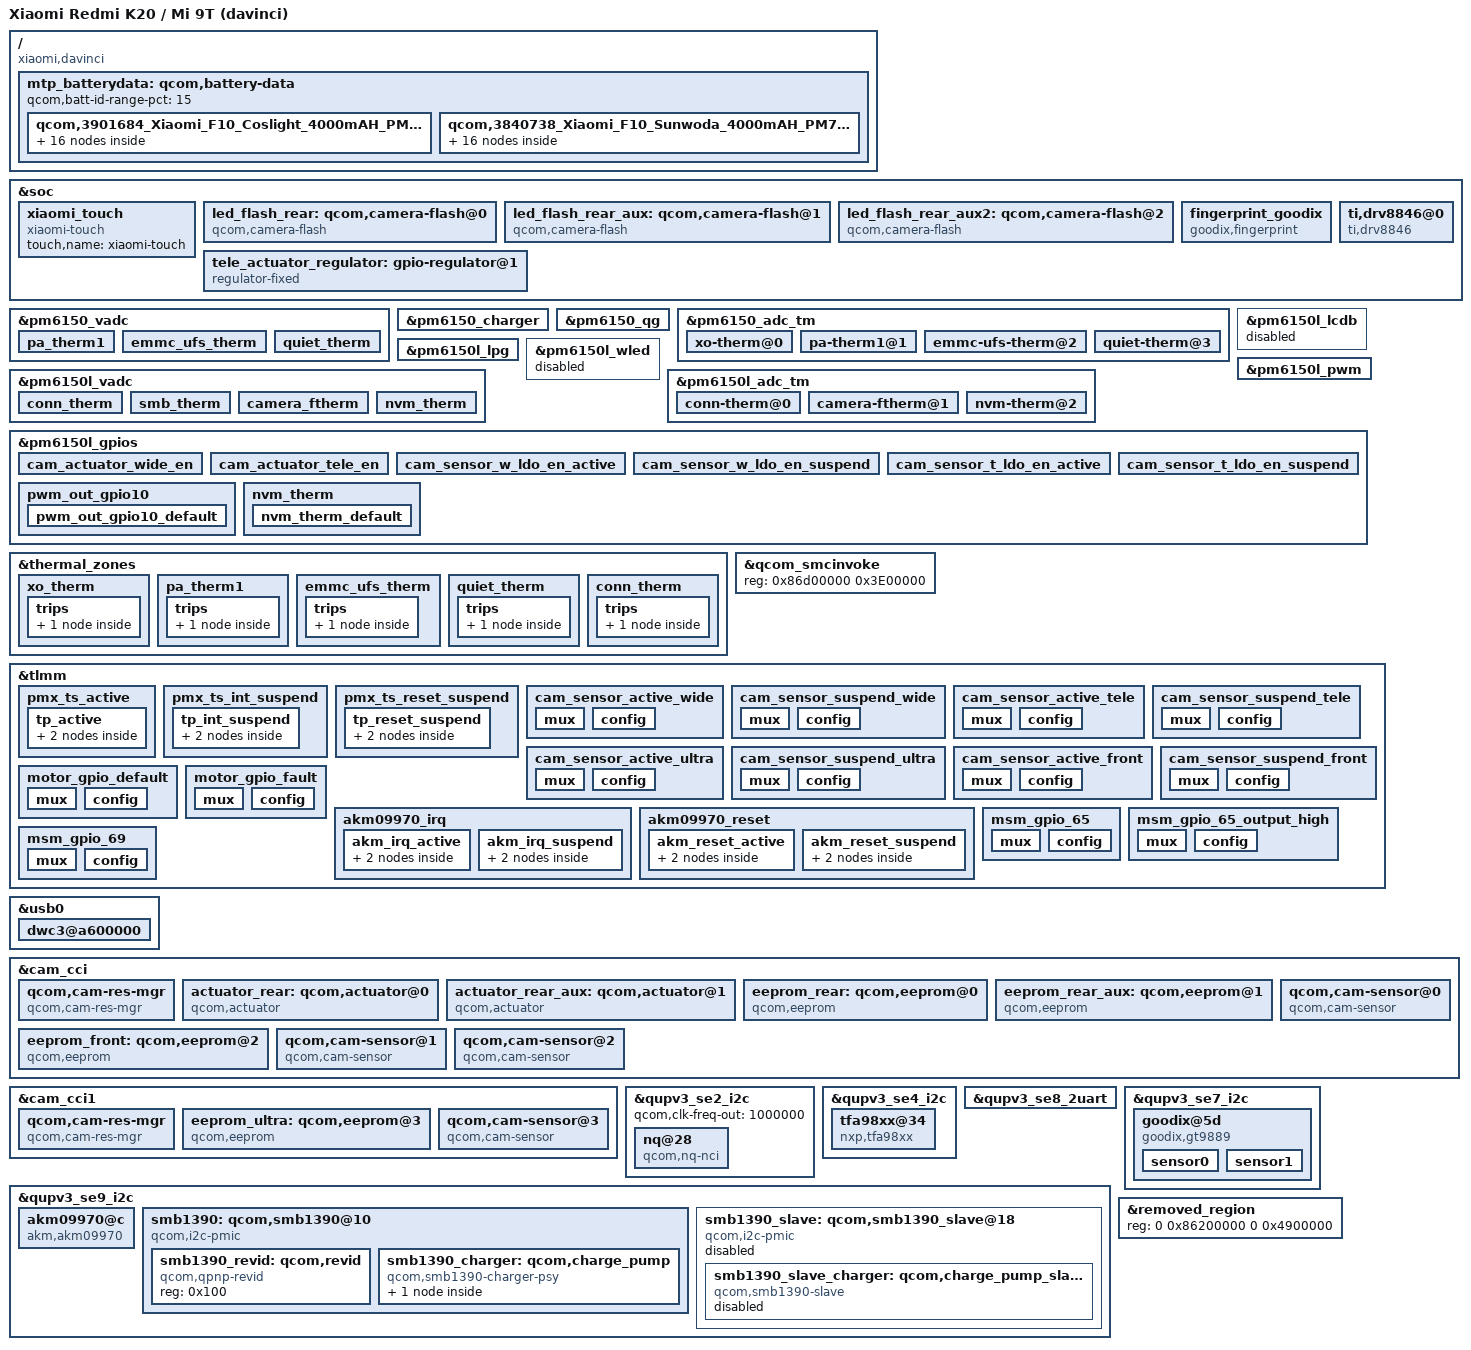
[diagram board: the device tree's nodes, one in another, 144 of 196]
/dts-v1/;

/* Generated by dtsplit.py (tools-sdmmagpie) from the 4.14 davinci files and the 6.1 violet DT. */

#include "xiaomi-sdmmagpie-common.dtsi"
#define wide_actuator_regulator tele_actuator_regulator

/ {
	/* MERGE model: 4.14 target has "DAVINCI" */
	/* MERGE compatible: 4.14 target has "qcom,sdmmagpie-qrd", "qcom,sdmmagpie", "qcom,qrd" */
	model = "Xiaomi Redmi K20 / Mi 9T (davinci)";
	compatible = "xiaomi,davinci", "qcom,sdmmagpie";
	qcom,board-id = <39 0>;

	/* davinci battery profiles (4.14 davinci-sdmmagpie.dtsi) */
	mtp_batterydata: qcom,battery-data {
		qcom,batt-id-range-pct = <15>;

		qcom,3901684_Xiaomi_F10_Coslight_4000mAH_PM7150 {
			qcom,max-voltage-uv = <4400000>;
			qcom,fg-cc-cv-threshold-uv = <4390000>;
			qcom,fastchg-current-ma = <3500>;
			qcom,jeita-fcc-ranges = <0 50 390000 51 100 1170000 101 150 2730000 151 450 3500000 451 580 1950000>;
			qcom,jeita-fv-ranges = <0 50 4400000 51 100 4400000 101 150 4400000 151 450 4400000 451 580 4100000>;
			qcom,dynamic-fv-ranges = <0 100 4400000 101 200 4380000 201 300 4360000 301 400 4340000 401 500 4340000>;
			qcom,fg-cc-cv-threshold-mv = <4390>;
			qcom,nom-batt-capacity-mah = <4000>;
			qcom,batt-id-kohm = <100>;
			qcom,battery-beta = <4250>;
			qcom,battery-therm-kohm = <100>;
			qcom,battery-type = "f10_coslt";
			qcom,qg-batt-profile-ver = <100>;

			qcom,fcc1-temp-lut {
				qcom,lut-col-legend = <0 10 25 40 50>;
				qcom,lut-data = <3846 3933 4032 4068 4080>;
			};

			qcom,fcc2-temp-lut {
				qcom,lut-col-legend = <(-10) 0 10 25 40 50>;
				qcom,lut-data = <4019 4020 4036 4042 4039 4040>;
			};

			qcom,pc-temp-v1-lut {
				qcom,lut-col-legend = <0 10 25 40 50>;
				qcom,lut-row-legend = <10000 9800 9600 9400 9200>, <9000 8800 8600 8400 8200>, <8000 7800 7600 7400 7200>, <7000 6800 6600 6400 6200>, <6000 5800 5600 5400 5200>, <5000 4800 4600 4400 4200>, <4000 3800 3600 3400 3200>, <3000 2800 2600 2400 2200>, <2000 1800 1600 1400 1200>, <1000 900 800 700 600>, <500 400 300 200 100>, <0>;
				qcom,lut-data = <43488 43668 43810 43851 43860>, <43204 43386 43568 43592 43593>, <42945 43123 43311 43350 43352>, <42701 42877 43059 43112 43117>, <42462 42641 42816 42873 42880>, <42232 42405 42577 42634 42643>, <42008 42173 42339 42398 42407>, <41791 41948 42102 42164 42173>, <41583 41727 41871 41932 41942>, <41392 41514 41644 41702 41714>, <41221 41322 41424 41473 41488>, <41034 41147 41220 41251 41267>, <40791 40954 41030 41034 41048>, <40521 40708 40828 40824 40836>, <40287 40448 40590 40620 40631>, <40082 40232 40355 40424 40434>, <39904 40042 40169 40238 40245>, <39761 39879 40009 40063 40067>, <39639 39743 39857 39894 39896>, <39519 39621 39716 39738 39740>, <39396 39491 39567 39584 39588>, <39275 39356 39372 39388 39398>, <39158 39214 39137 39126 39135>, <39043 39048 38932 38904 38905>, <38935 38866 38758 38764 38769>, <38832 38707 38620 38654 38663>, <38733 38559 38531 38556 38559>, <38640 38442 38465 38470 38456>, <38550 38365 38402 38388 38365>, <38468 38305 38338 38306 38285>, <38396 38261 38279 38231 38214>, <38330 38230 38225 38166 38147>, <38286 38202 38175 38110 38085>, <38262 38174 38127 38057 38026>, <38242 38149 38084 38008 37972>, <38212 38120 38042 37960 37919>, <38172 38091 38003 37913 37866>, <38126 38056 37963 37866 37813>, <38071 38006 37909 37804 37745>, <38004 37936 37827 37716 37652>, <37920 37851 37728 37612 37543>, <37805 37742 37612 37504 37433>, <37672 37611 37477 37380 37309>, <37517 37451 37322 37226 37149>, <37364 37299 37182 37088 37017>, <37251 37194 37084 36995 36937>, <37212 37155 37052 36969 36910>, <37178 37125 37037 36946 36888>, <37148 37101 37015 36926 36869>, <37099 37057 36972 36878 36809>, <36922 36861 36756 36633 36536>, <36490 36427 36327 36199 36099>, <35920 35855 35755 35625 35525>, <35147 35075 34970 34840 34741>, <33910 33851 33747 33621 33517>, <30000 30000 30000 30000 30000>;
			};

			qcom,pc-temp-v2-lut {
				qcom,lut-col-legend = <(-10) 0 10 25 40 50>;
				qcom,lut-row-legend = <10000 9800 9600 9400 9200 9000>, <8800 8600 8400 8200 8000 7800>, <7600 7400 7200 7000 6800 6600>, <6400 6200 6000 5800 5600 5400>, <5200 5000 4800 4600 4400 4200>, <4000 3800 3600 3400 3200 3000>, <2800 2600 2400 2200 2000 1800>, <1600 1400 1200 1000 900 800>, <700 600 500 400 300 200>, <100 0>;
				qcom,lut-data = <43870 43840 43820 43790 43750 43735>, <43457 43465 43479 43488 43457 43446>, <43083 43120 43164 43203 43180 43174>, <42755 42809 42879 42939 42922 42918>, <42466 42530 42622 42694 42681 42679>, <42199 42266 42374 42454 42445 42444>, <41950 42011 42125 42215 42209 42207>, <41717 41769 41882 41979 41974 41972>, <41486 41534 41646 41748 41743 41741>, <41254 41301 41414 41521 41515 41514>, <41060 41106 41197 41298 41292 41290>, <40933 40978 41007 41082 41075 41070>, <40811 40857 40821 40869 40862 40854>, <40558 40626 40599 40660 40656 40649>, <40083 40219 40341 40451 40453 40448>, <39699 39874 40110 40251 40259 40256>, <39494 39664 39930 40057 40075 40071>, <39331 39489 39759 39874 39898 39893>, <39161 39308 39564 39714 39732 39726>, <38993 39127 39353 39572 39575 39571>, <38836 38956 39146 39401 39399 39397>, <38687 38791 38939 39162 39176 39180>, <38551 38638 38746 38920 38951 38960>, <38437 38500 38588 38739 38766 38774>, <38339 38375 38451 38586 38602 38607>, <38253 38271 38330 38457 38467 38470>, <38176 38189 38219 38348 38358 38359>, <38106 38119 38125 38252 38263 38261>, <38039 38057 38054 38163 38175 38171>, <37975 38002 37996 38081 38096 38087>, <37913 37951 37943 38008 38025 38015>, <37851 37902 37895 37940 37962 37951>, <37791 37854 37850 37878 37901 37890>, <37730 37806 37806 37824 37837 37825>, <37671 37759 37763 37775 37772 37756>, <37613 37710 37716 37724 37700 37675>, <37556 37657 37665 37673 37619 37573>, <37499 37600 37608 37616 37534 37472>, <37443 37536 37543 37547 37455 37389>, <37388 37466 37471 37468 37376 37314>, <37331 37387 37389 37380 37293 37234>, <37272 37293 37292 37280 37206 37151>, <37209 37190 37188 37162 37094 37039>, <37139 37086 37078 37031 36957 36896>, <37057 36996 36968 36923 36855 36802>, <36948 36906 36845 36854 36804 36754>, <36887 36876 36802 36838 36794 36743>, <36813 36823 36763 36818 36777 36726>, <36723 36763 36717 36783 36745 36693>, <36595 36669 36638 36690 36640 36571>, <36369 36466 36437 36389 36312 36217>, <36002 36054 36001 35863 35794 35699>, <35445 35432 35359 35185 35122 35015>, <34591 34546 34467 34229 34190 34081>, <33142 33098 33118 32916 32929 32822>, <28835 28221 27917 27830 28084 28065>;
			};

			qcom,pc-temp-z1-lut {
				qcom,lut-col-legend = <0 10 25 40 50>;
				qcom,lut-row-legend = <10000 9800 9600 9400 9200>, <9000 8800 8600 8400 8200>, <8000 7800 7600 7400 7200>, <7000 6800 6600 6400 6200>, <6000 5800 5600 5400 5200>, <5000 4800 4600 4400 4200>, <4000 3800 3600 3400 3200>, <3000 2800 2600 2400 2200>, <2000 1800 1600 1400 1200>, <1000 900 800 700 600>, <500 400 300 200 100>, <0>;
				qcom,lut-data = <13676 12824 12149 11863 11725>, <13757 12862 12176 11884 11753>, <13750 12873 12181 11877 11749>, <13740 12865 12182 11863 11738>, <13721 12854 12172 11851 11729>, <13690 12851 12156 11840 11719>, <13677 12847 12147 11833 11712>, <13679 12840 12141 11827 11706>, <13682 12823 12138 11823 11701>, <13676 12805 12140 11819 11699>, <13643 12798 12143 11816 11697>, <13602 12796 12143 11816 11697>, <13561 12791 12143 11815 11698>, <13514 12763 12140 11815 11699>, <13485 12734 12125 11815 11700>, <13464 12731 12111 11817 11701>, <13451 12737 12114 11819 11702>, <13442 12744 12126 11821 11706>, <13420 12757 12136 11823 11709>, <13410 12773 12143 11826 11711>, <13430 12782 12147 11829 11713>, <13452 12789 12149 11833 11715>, <13457 12794 12149 11837 11717>, <13462 12802 12149 11839 11719>, <13467 12813 12147 11840 11722>, <13470 12818 12146 11841 11724>, <13473 12819 12152 11843 11728>, <13476 12820 12166 11849 11732>, <13480 12824 12172 11854 11737>, <13486 12829 12171 11859 11742>, <13491 12835 12170 11864 11746>, <13497 12842 12170 11869 11751>, <13507 12850 12172 11876 11757>, <13534 12865 12175 11881 11762>, <13560 12886 12183 11887 11769>, <13561 12897 12191 11893 11776>, <13549 12904 12198 11899 11781>, <13541 12912 12206 11906 11785>, <13554 12920 12211 11909 11790>, <13582 12930 12215 11912 11797>, <13611 12938 12218 11914 11802>, <13651 12943 12227 11919 11805>, <13680 12949 12236 11926 11808>, <13698 12961 12242 11928 11811>, <13664 12976 12249 11931 11816>, <13665 12976 12271 11939 11820>, <13661 12955 12257 11939 11820>, <13647 12969 12248 11936 11820>, <13654 12983 12270 11940 11823>, <13680 12977 12269 11953 11834>, <13683 12995 12281 11963 11839>, <13680 13009 12271 11965 11851>, <13730 13048 12310 11977 11861>, <13762 13082 12328 11996 11885>, <13762 13082 12328 11996 11885>, <13762 13082 12328 11996 11885>;
			};

			qcom,pc-temp-z2-lut {
				qcom,lut-col-legend = <0 10 25 40 50>;
				qcom,lut-row-legend = <10000 9800 9600 9400 9200>, <9000 8800 8600 8400 8200>, <8000 7800 7600 7400 7200>, <7000 6800 6600 6400 6200>, <6000 5800 5600 5400 5200>, <5000 4800 4600 4400 4200>, <4000 3800 3600 3400 3200>, <3000 2800 2600 2400 2200>, <2000 1800 1600 1400 1200>, <1000 900 800 700 600>, <500 400 300 200 100>, <0>;
				qcom,lut-data = <9450 9498 10356 10429 10332>, <9960 10130 10298 10398 10361>, <10130 10317 10438 10460 10380>, <10228 10298 10522 10512 10414>, <10231 10268 10495 10503 10430>, <10214 10239 10448 10467 10425>, <10198 10209 10409 10424 10408>, <10180 10191 10369 10366 10380>, <10164 10182 10349 10323 10352>, <10163 10177 10347 10331 10342>, <10170 10189 10349 10366 10333>, <10175 10269 10356 10386 10328>, <10164 10324 10371 10396 10332>, <10142 10280 10388 10403 10337>, <10136 10208 10423 10409 10330>, <10214 10194 10460 10415 10305>, <10301 10211 10471 10413 10292>, <10279 10235 10476 10394 10292>, <10174 10266 10484 10380 10299>, <10109 10302 10500 10390 10317>, <10097 10330 10523 10420 10351>, <10090 10354 10554 10483 10426>, <10088 10372 10591 10650 10668>, <10087 10385 10600 10752 10839>, <10087 10394 10566 10630 10700>, <10093 10395 10528 10442 10449>, <10105 10395 10517 10422 10425>, <10119 10397 10510 10482 10589>, <10140 10410 10509 10516 10690>, <10162 10432 10514 10505 10563>, <10181 10444 10521 10483 10369>, <10199 10448 10523 10453 10302>, <10194 10452 10523 10411 10272>, <9887 10459 10526 10396 10259>, <9517 10470 10538 10404 10253>, <9481 10484 10554 10422 10253>, <9559 10506 10573 10452 10281>, <9652 10526 10596 10505 10363>, <9790 10500 10620 10551 10423>, <9948 10408 10646 10592 10461>, <9986 10370 10669 10619 10482>, <9963 10383 10689 10624 10476>, <9939 10358 10701 10620 10464>, <9914 10295 10685 10590 10500>, <9800 12043 10702 10572 10499>, <9756 15846 10733 10546 10435>, <9764 13719 10726 10542 10447>, <9771 14156 10705 10558 10467>, <9740 15920 10736 10601 10544>, <9733 15952 10790 10756 10632>, <9673 13590 10784 10574 10420>, <9525 12191 10699 10408 10277>, <9456 11187 10615 10352 10215>, <9398 10638 10493 10293 10167>, <9398 10638 10493 10293 10167>, <9398 10638 10493 10293 10167>;
			};

			qcom,pc-temp-z3-lut {
				qcom,lut-col-legend = <0 10 25 40 50>;
				qcom,lut-row-legend = <10000 9800 9600 9400 9200>, <9000 8800 8600 8400 8200>, <8000 7800 7600 7400 7200>, <7000 6800 6600 6400 6200>, <6000 5800 5600 5400 5200>, <5000 4800 4600 4400 4200>, <4000 3800 3600 3400 3200>, <3000 2800 2600 2400 2200>, <2000 1800 1600 1400 1200>, <1000 900 800 700 600>, <500 400 300 200 100>, <0>;
				qcom,lut-data = <19584 19352 19356 19353 19346>, <19659 19520 19400 19388 19372>, <19680 19596 19446 19401 19385>, <19689 19617 19467 19408 19394>, <19672 19626 19470 19414 19402>, <19620 19626 19472 19419 19410>, <19593 19624 19473 19421 19413>, <19592 19621 19474 19418 19411>, <19592 19616 19474 19414 19408>, <19593 19609 19469 19410 19404>, <19598 19604 19461 19406 19398>, <19605 19596 19452 19403 19393>, <19619 19590 19442 19401 19390>, <19639 19577 19437 19399 19387>, <19654 19557 19438 19395 19384>, <19672 19543 19438 19389 19380>, <19685 19534 19434 19384 19376>, <19669 19523 19424 19380 19372>, <19620 19503 19417 19376 19367>, <19594 19483 19413 19372 19362>, <19594 19480 19411 19369 19356>, <19597 19484 19415 19370 19356>, <19602 19488 19425 19382 19369>, <19614 19498 19429 19390 19378>, <19621 19514 19426 19381 19369>, <19623 19519 19421 19366 19352>, <19625 19520 19419 19365 19356>, <19625 19519 19417 19373 19394>, <19626 19519 19417 19382 19418>, <19626 19520 19420 19396 19413>, <19625 19519 19423 19408 19403>, <19618 19514 19425 19408 19396>, <19602 19508 19427 19401 19389>, <19467 19502 19427 19395 19382>, <19308 19496 19425 19388 19374>, <19277 19490 19423 19381 19366>, <19271 19485 19418 19375 19359>, <19268 19479 19413 19369 19353>, <19265 19452 19409 19367 19351>, <19263 19394 19406 19367 19352>, <19262 19366 19404 19367 19353>, <19263 19306 19403 19366 19354>, <19263 19262 19402 19364 19355>, <19263 19262 19399 19364 19361>, <19264 19259 19391 19362 19360>, <19264 19257 19381 19355 19350>, <19264 19257 19382 19346 19341>, <19264 19257 19359 19344 19336>, <19264 19257 19354 19340 19323>, <19264 19257 19351 19325 19320>, <19265 19257 19355 19350 19350>, <19269 19258 19360 19361 19360>, <19271 19259 19357 19362 19362>, <19273 19260 19359 19361 19356>, <19273 19260 19359 19361 19356>, <19273 19260 19359 19361 19356>;
			};

			qcom,pc-temp-z4-lut {
				qcom,lut-col-legend = <0 10 25 40 50>;
				qcom,lut-row-legend = <10000 9800 9600 9400 9200>, <9000 8800 8600 8400 8200>, <8000 7800 7600 7400 7200>, <7000 6800 6600 6400 6200>, <6000 5800 5600 5400 5200>, <5000 4800 4600 4400 4200>, <4000 3800 3600 3400 3200>, <3000 2800 2600 2400 2200>, <2000 1800 1600 1400 1200>, <1000 900 800 700 600>, <500 400 300 200 100>, <0>;
				qcom,lut-data = <16349 15716 15054 14902 14889>, <16932 15709 15207 15010 14935>, <16706 15677 15124 14968 14917>, <16405 15498 15032 14902 14871>, <16187 15279 14958 14858 14836>, <15992 15152 14891 14822 14807>, <15824 15056 14842 14794 14782>, <15675 14980 14803 14770 14757>, <15542 14921 14773 14751 14738>, <15426 14872 14750 14737 14730>, <15322 14823 14732 14726 14726>, <15232 14770 14719 14717 14722>, <15158 14740 14709 14710 14717>, <15096 14739 14705 14705 14711>, <15034 14745 14707 14701 14707>, <14957 14742 14709 14698 14704>, <14895 14736 14706 14694 14700>, <14881 14732 14695 14689 14695>, <14889 14729 14684 14683 14691>, <14890 14726 14675 14677 14685>, <14871 14721 14669 14673 14679>, <14845 14708 14687 14684 14686>, <14821 14700 14744 14756 14754>, <14797 14711 14791 14811 14811>, <14778 14738 14827 14823 14820>, <14766 14759 14849 14829 14824>, <14757 14791 14841 14824 14815>, <14751 14811 14814 14796 14759>, <14747 14807 14789 14765 14717>, <14744 14792 14768 14737 14708>, <14743 14776 14749 14712 14702>, <14743 14757 14732 14700 14696>, <14748 14738 14716 14693 14690>, <14879 14723 14706 14689 14686>, <15037 14710 14699 14687 14685>, <15057 14700 14694 14686 14684>, <15042 14691 14690 14684 14682>, <15027 14685 14686 14681 14680>, <15015 14706 14686 14680 14680>, <15003 14765 14688 14687 14689>, <14995 14791 14690 14694 14698>, <14990 14849 14688 14690 14693>, <14984 14892 14685 14682 14683>, <14973 14889 14684 14683 14686>, <14915 14861 14675 14677 14680>, <14896 14837 14658 14658 14657>, <14892 14830 14648 14656 14655>, <14886 14824 14657 14644 14644>, <14878 14815 14651 14631 14635>, <14873 14811 14650 14638 14629>, <14874 14821 14664 14644 14646>, <14903 14843 14674 14650 14653>, <14923 14854 14683 14655 14659>, <14946 14870 14688 14663 14671>, <14946 14870 14688 14663 14671>, <14946 14870 14688 14663 14671>;
			};

			qcom,pc-temp-z5-lut {
				qcom,lut-col-legend = <0 10 25 40 50>;
				qcom,lut-row-legend = <10000 9800 9600 9400 9200>, <9000 8800 8600 8400 8200>, <8000 7800 7600 7400 7200>, <7000 6800 6600 6400 6200>, <6000 5800 5600 5400 5200>, <5000 4800 4600 4400 4200>, <4000 3800 3600 3400 3200>, <3000 2800 2600 2400 2200>, <2000 1800 1600 1400 1200>, <1000 900 800 700 600>, <500 400 300 200 100>, <0>;
				qcom,lut-data = <12068 11805 13105 14794 14476>, <12682 13663 14517 16476 16584>, <13059 14803 16164 17427 17425>, <13339 15366 17399 18166 18528>, <13521 15816 18166 19089 19689>, <13671 16354 18845 20011 20860>, <13821 16934 19850 20564 21968>, <14032 17605 21219 20921 23164>, <14296 18400 22511 21323 24051>, <14526 19246 23717 22058 24084>, <14722 20355 24682 23149 23878>, <14977 22381 25011 24202 23807>, <15447 23829 25072 25332 24409>, <16055 24330 25398 26277 25312>, <16684 24777 28353 26744 25951>, <18399 25088 31787 26886 26556>, <20005 25071 31433 26861 27134>, <19477 24647 29122 27312 27751>, <17227 22780 28219 28003 28165>, <16028 20648 30088 28951 28372>, <16307 20698 33450 30371 28789>, <16872 22949 39426 32478 29794>, <17731 26251 48734 36284 32673>, <19374 35028 51577 38412 34634>, <21171 48727 43042 31788 29235>, <22986 53682 32940 21734 19795>, <25142 52124 28773 19776 18837>, <27702 49566 26042 19634 24638>, <31349 48095 25391 19762 28758>, <33917 46489 25900 23615 29254>, <34214 44620 26850 29088 29587>, <34319 41836 28704 31752 30507>, <33970 39347 31933 33664 32360>, <24494 38187 35347 34897 33251>, <13047 37314 39698 35771 33141>, <11330 36519 42444 36291 32872>, <11293 35785 42135 35950 32238>, <11280 34945 41098 34863 30963>, <11283 32441 39932 34083 30210>, <11292 27797 38401 33668 29975>, <11306 25841 36924 33125 29744>, <11357 17804 35863 30938 29041>, <11396 11760 34701 28209 28242>, <11420 11783 32202 28711 31717>, <11663 11863 31291 28853 32969>, <11696 11770 30257 27411 27639>, <11631 11755 32521 22995 22679>, <11593 11707 21689 24268 23072>, <11588 11640 21033 26370 21154>, <11606 11672 21179 20038 21192>, <11676 11783 19812 26887 31299>, <11747 11696 18623 25719 28100>, <11603 11583 17171 23479 24321>, <11481 11457 16600 20465 18831>, <11481 11457 16600 20465 18831>, <11481 11457 16600 20465 18831>;
			};

			qcom,pc-temp-z6-lut {
				qcom,lut-col-legend = <0 10 25 40 50>;
				qcom,lut-row-legend = <10000 9800 9600 9400 9200>, <9000 8800 8600 8400 8200>, <8000 7800 7600 7400 7200>, <7000 6800 6600 6400 6200>, <6000 5800 5600 5400 5200>, <5000 4800 4600 4400 4200>, <4000 3800 3600 3400 3200>, <3000 2800 2600 2400 2200>, <2000 1800 1600 1400 1200>, <1000 900 800 700 600>, <500 400 300 200 100>, <0>;
				qcom,lut-data = <16575 15671 14966 14758 14711>, <16822 15705 15040 14822 14747>, <16676 15702 15015 14806 14743>, <16479 15603 14983 14780 14728>, <16322 15474 14946 14762 14716>, <16172 15393 14908 14746 14706>, <16049 15328 14880 14732 14696>, <15953 15275 14857 14718 14684>, <15872 15232 14838 14706 14673>, <15802 15194 14822 14697 14666>, <15740 15156 14808 14689 14661>, <15683 15120 14797 14683 14656>, <15626 15090 14788 14679 14652>, <15573 15067 14781 14675 14648>, <15530 15050 14778 14671 14644>, <15494 15040 14775 14667 14641>, <15463 15033 14771 14662 14637>, <15436 15027 14762 14657 14633>, <15413 15020 14756 14653 14628>, <15400 15014 14752 14649 14623>, <15392 15013 14750 14646 14618>, <15387 15014 14760 14652 14622>, <15387 15015 14791 14691 14659>, <15387 15025 14815 14718 14688>, <15387 15048 14830 14718 14686>, <15386 15065 14839 14716 14682>, <15385 15081 14836 14712 14679>, <15386 15090 14825 14706 14677>, <15390 15089 14817 14700 14673>, <15394 15087 14811 14696 14668>, <15394 15084 14806 14693 14661>, <15394 15077 14802 14689 14656>, <15394 15068 14797 14683 14650>, <15388 15062 14795 14679 14646>, <15379 15057 14793 14676 14642>, <15376 15054 14791 14673 14638>, <15374 15053 14790 14670 14635>, <15373 15053 14789 14667 14631>, <15376 15054 14789 14666 14630>, <15382 15057 14791 14670 14635>, <15387 15059 14793 14675 14641>, <15393 15060 14795 14673 14639>, <15401 15063 14798 14671 14637>, <15412 15074 14800 14672 14641>, <15409 15072 14797 14670 14639>, <15403 15065 14788 14659 14625>, <15404 15063 14785 14654 14620>, <15401 15062 14778 14648 14613>, <15400 15060 14776 14641 14603>, <15402 15065 14777 14639 14600>, <15415 15079 14790 14657 14625>, <15441 15098 14803 14669 14637>, <15466 15115 14811 14676 14644>, <15503 15144 14824 14684 14651>, <15503 15144 14824 14684 14651>, <15503 15144 14824 14684 14651>;
			};

			qcom,pc-temp-y1-lut {
				qcom,lut-col-legend = <(-10) 0 10 25 40 50>;
				qcom,lut-row-legend = <10000 9800 9600 9400 9200 9000>, <8800 8600 8400 8200 8000 7800>, <7600 7400 7200 7000 6800 6600>, <6400 6200 6000 5800 5600 5400>, <5200 5000 4800 4600 4400 4200>, <4000 3800 3600 3400 3200 3000>, <2800 2600 2400 2200 2000 1800>, <1600 1400 1200 1000 900 800>, <700 600 500 400 300 200>, <100 0>;
				qcom,lut-data = <6782 6302 5878 5528 5347 5264>, <6783 6301 5874 5519 5345 5264>, <6787 6300 5873 5513 5342 5263>, <6791 6298 5874 5509 5340 5262>, <6794 6297 5876 5507 5338 5261>, <6797 6295 5878 5507 5337 5259>, <6808 6294 5884 5510 5335 5256>, <6824 6293 5891 5514 5335 5253>, <6825 6291 5891 5514 5333 5252>, <6816 6286 5887 5509 5331 5251>, <6811 6283 5885 5507 5330 5250>, <6815 6284 5887 5510 5330 5249>, <6819 6287 5890 5515 5330 5249>, <6827 6290 5895 5514 5329 5248>, <6854 6294 5902 5508 5327 5248>, <6869 6296 5906 5505 5326 5247>, <6859 6297 5904 5509 5327 5247>, <6844 6299 5902 5515 5329 5248>, <6845 6304 5903 5518 5329 5248>, <6866 6320 5904 5519 5330 5250>, <6879 6331 5905 5520 5330 5251>, <6863 6337 5904 5521 5332 5252>, <6840 6341 5904 5522 5334 5253>, <6839 6339 5907 5523 5336 5255>, <6848 6329 5911 5524 5339 5257>, <6859 6321 5913 5524 5341 5260>, <6873 6318 5908 5524 5342 5262>, <6885 6316 5903 5525 5344 5265>, <6883 6315 5905 5527 5346 5268>, <6864 6313 5913 5528 5348 5272>, <6849 6311 5915 5530 5352 5276>, <6841 6307 5913 5533 5357 5279>, <6835 6304 5912 5535 5362 5282>, <6837 6304 5913 5537 5363 5284>, <6848 6305 5915 5539 5364 5287>, <6854 6306 5916 5540 5365 5288>, <6842 6307 5911 5541 5367 5290>, <6826 6308 5907 5542 5369 5292>, <6827 6309 5906 5542 5371 5293>, <6844 6308 5906 5541 5373 5295>, <6855 6307 5906 5543 5374 5296>, <6842 6313 5913 5549 5376 5298>, <6830 6319 5918 5551 5377 5302>, <6857 6313 5921 5552 5380 5309>, <6861 6316 5928 5555 5386 5314>, <6935 6379 5949 5562 5392 5318>, <6903 6377 5952 5571 5392 5318>, <6914 6354 5954 5570 5394 5318>, <6935 6362 5951 5565 5393 5317>, <6950 6380 5967 5569 5393 5317>, <6936 6378 5973 5576 5397 5322>, <7003 6410 5978 5586 5403 5330>, <7023 6448 6012 5609 5419 5340>, <7114 6478 6045 5631 5434 5352>, <7114 6478 6045 5631 5434 5352>, <7114 6478 6045 5631 5434 5352>;
			};

			qcom,pc-temp-y2-lut {
				qcom,lut-col-legend = <(-10) 0 10 25 40 50>;
				qcom,lut-row-legend = <10000 9800 9600 9400 9200 9000>, <8800 8600 8400 8200 8000 7800>, <7600 7400 7200 7000 6800 6600>, <6400 6200 6000 5800 5600 5400>, <5200 5000 4800 4600 4400 4200>, <4000 3800 3600 3400 3200 3000>, <2800 2600 2400 2200 2000 1800>, <1600 1400 1200 1000 900 800>, <700 600 500 400 300 200>, <100 0>;
				qcom,lut-data = <9660 9664 9643 11400 11301 11201>, <9660 9665 9748 11354 11250 11169>, <9661 9667 9949 11308 11201 11135>, <9661 9669 10162 11263 11154 11100>, <9662 9671 10340 11220 11112 11067>, <9662 9673 10434 11177 11075 11038>, <9663 9676 10464 11134 11043 11011>, <9663 9678 10486 11093 11015 10985>, <9663 9679 10514 11065 10988 10955>, <9664 9679 10550 11043 10960 10922>, <9664 9679 10594 11026 10948 10899>, <9665 9681 10678 11010 10965 10886>, <9665 9683 10775 10999 10987 10878>, <9665 9683 10833 11005 10985 10879>, <9665 9679 10879 11039 10967 10888>, <9665 9677 10925 11082 10960 10893>, <9665 9676 10989 11140 10988 10907>, <9665 9675 11042 11211 11040 10931>, <9665 9675 11053 11297 11121 10978>, <9665 9675 11053 11398 11250 11086>, <9665 9675 11048 11432 11323 11166>, <9665 9675 10794 11380 11329 11226>, <9665 9674 10479 11327 11318 11265>, <9664 9674 10424 11335 11307 11248>, <9664 9674 10398 11368 11288 11201>, <9664 9673 10349 11396 11284 11184>, <9664 9672 10059 11416 11302 11197>, <9664 9671 9802 11433 11323 11216>, <9664 9670 9779 11443 11341 11239>, <9664 9669 9765 11451 11375 11271>, <9664 9668 9749 11456 11410 11302>, <9664 9667 9728 11462 11452 11343>, <9663 9667 9710 11467 11480 11376>, <9663 9666 9701 11466 11475 11380>, <9663 9665 9694 11462 11462 11367>, <9663 9665 9690 11455 11448 11350>, <9663 9664 9686 11433 11427 11304>, <9663 9663 9682 11403 11403 11250>, <9662 9663 9678 11369 11370 11209>, <9662 9662 9675 11330 11335 11176>, <9662 9662 9672 11290 11318 11171>, <9662 9661 9669 11245 11288 11197>, <9661 9661 9667 11177 11257 11184>, <9661 9661 9664 11081 11215 11123>, <9660 9660 9663 11000 11116 11034>, <9660 9660 9663 10934 11068 10915>, <9660 10938 9662 10945 11098 10909>, <9660 9866 9662 10938 11117 10940>, <9659 9659 9661 10942 11138 11017>, <9659 9659 9661 10956 11152 10981>, <9658 9659 9660 10862 11113 10886>, <9658 9658 9659 10706 10976 10822>, <9657 9657 9658 10554 10898 10737>, <9654 9657 9657 10421 10803 10620>, <9654 9657 9657 10421 10803 10620>, <9654 9657 9657 10421 10803 10620>;
			};

			qcom,pc-temp-y3-lut {
				qcom,lut-col-legend = <(-10) 0 10 25 40 50>;
				qcom,lut-row-legend = <10000 9800 9600 9400 9200 9000>, <8800 8600 8400 8200 8000 7800>, <7600 7400 7200 7000 6800 6600>, <6400 6200 6000 5800 5600 5400>, <5200 5000 4800 4600 4400 4200>, <4000 3800 3600 3400 3200 3000>, <2800 2600 2400 2200 2000 1800>, <1600 1400 1200 1000 900 800>, <700 600 500 400 300 200>, <100 0>;
				qcom,lut-data = <14377 13882 13427 13298 13280 13279>, <14276 13837 13425 13298 13281 13279>, <14179 13793 13422 13299 13282 13280>, <14089 13752 13418 13300 13283 13281>, <14010 13714 13415 13301 13284 13282>, <13945 13680 13412 13302 13285 13282>, <13896 13651 13408 13303 13286 13282>, <13854 13623 13405 13304 13286 13283>, <13802 13594 13406 13305 13287 13283>, <13736 13560 13412 13306 13287 13284>, <13705 13538 13414 13307 13287 13285>, <13706 13529 13394 13309 13290 13286>, <13710 13522 13368 13310 13293 13286>, <13700 13509 13366 13311 13293 13287>, <13661 13485 13370 13312 13294 13289>, <13639 13466 13371 13312 13294 13291>, <13639 13453 13368 13310 13295 13291>, <13639 13442 13363 13307 13297 13292>, <13640 13433 13356 13307 13297 13292>, <13643 13425 13347 13307 13295 13293>, <13645 13420 13340 13307 13293 13293>, <13645 13418 13334 13303 13290 13289>, <13645 13417 13330 13298 13287 13285>, <13646 13416 13327 13295 13285 13282>, <13652 13414 13324 13294 13283 13280>, <13660 13414 13319 13293 13282 13279>, <13675 13422 13296 13293 13282 13279>, <13693 13435 13275 13292 13282 13280>, <13712 13448 13275 13292 13282 13279>, <13732 13465 13280 13291 13282 13278>, <13752 13483 13286 13291 13282 13278>, <13774 13501 13296 13291 13282 13278>, <13798 13521 13308 13291 13283 13279>, <13822 13543 13320 13291 13283 13279>, <13845 13569 13331 13292 13283 13280>, <13871 13595 13344 13292 13283 13280>, <13900 13622 13357 13293 13283 13279>, <13932 13650 13374 13293 13283 13279>, <13966 13682 13392 13294 13283 13280>, <14004 13720 13415 13294 13284 13282>, <14043 13758 13443 13295 13284 13283>, <14083 13797 13480 13296 13285 13283>, <14127 13838 13524 13296 13284 13283>, <14183 13882 13577 13295 13282 13280>, <14247 13935 13629 13297 13283 13283>, <14240 13947 13620 13298 13287 13286>, <14296 13698 13672 13304 13291 13289>, <14360 13985 13715 13309 13294 13291>, <14429 14092 13758 13314 13295 13292>, <14516 14141 13796 13317 13294 13290>, <14609 14202 13840 13314 13291 13287>, <14738 14280 13919 13316 13292 13289>, <14958 14419 14080 13330 13298 13294>, <15801 14628 14268 13356 13307 13303>, <15801 14628 14268 13356 13307 13303>, <15801 14628 14268 13356 13307 13303>;
			};

			qcom,pc-temp-y4-lut {
				qcom,lut-col-legend = <(-10) 0 10 25 40 50>;
				qcom,lut-row-legend = <10000 9800 9600 9400 9200 9000>, <8800 8600 8400 8200 8000 7800>, <7600 7400 7200 7000 6800 6600>, <6400 6200 6000 5800 5600 5400>, <5200 5000 4800 4600 4400 4200>, <4000 3800 3600 3400 3200 3000>, <2800 2600 2400 2200 2000 1800>, <1600 1400 1200 1000 900 800>, <700 600 500 400 300 200>, <100 0>;
				qcom,lut-data = <16879 16788 16672 16495 16474 16471>, <16913 16820 16686 16497 16472 16470>, <16954 16868 16709 16499 16471 16469>, <16994 16917 16734 16503 16470 16469>, <17028 16956 16754 16505 16469 16468>, <17047 16971 16762 16506 16469 16468>, <17053 16966 16761 16507 16469 16468>, <17058 16959 16758 16507 16470 16468>, <17072 16962 16753 16507 16471 16468>, <17115 16985 16739 16510 16473 16469>, <17151 17017 16733 16513 16475 16470>, <17177 17082 16802 16517 16476 16472>, <17199 17148 16892 16522 16477 16474>, <17149 17114 16886 16530 16480 16477>, <16924 16925 16820 16543 16486 16479>, <16789 16807 16786 16560 16494 16482>, <16781 16793 16786 16583 16503 16488>, <16776 16785 16786 16609 16514 16497>, <16762 16767 16773 16633 16537 16514>, <16733 16738 16729 16656 16572 16540>, <16708 16707 16683 16661 16585 16551>, <16689 16673 16641 16604 16559 16537>, <16674 16641 16602 16532 16520 16515>, <16668 16620 16575 16501 16492 16493>, <16665 16604 16552 16479 16466 16469>, <16663 16597 16547 16473 16459 16461>, <16661 16598 16567 16473 16459 16461>, <16658 16600 16588 16473 16460 16461>, <16658 16599 16590 16474 16464 16463>, <16658 16597 16587 16477 16470 16471>, <16659 16597 16584 16479 16478 16479>, <16661 16602 16580 16481 16489 16489>, <16665 16609 16577 16482 16496 16498>, <16669 16615 16579 16485 16496 16502>, <16674 16621 16585 16489 16496 16504>, <16680 16627 16591 16492 16494 16502>, <16688 16635 16599 16496 16480 16482>, <16699 16643 16606 16497 16469 16465>, <16713 16650 16615 16497 16469 16467>, <16733 16657 16625 16497 16470 16473>, <16756 16658 16630 16498 16473 16482>, <16782 16648 16633 16502 16486 16496>, <16809 16641 16640 16502 16484 16492>, <16837 16645 16657 16499 16463 16459>, <16839 16654 16661 16499 16457 16450>, <16759 16646 16641 16504 16470 16478>, <16772 16628 16676 16526 16496 16511>, <16787 16679 16711 16556 16530 16547>, <16802 16724 16754 16599 16567 16580>, <16815 16752 16798 16623 16569 16567>, <16815 16755 16806 16578 16505 16494>, <16812 16727 16770 16557 16489 16485>, <16812 16713 16759 16588 16504 16490>, <17025 16736 16768 16641 16549 16532>, <17025 16736 16768 16641 16549 16532>, <17025 16736 16768 16641 16549 16532>;
			};

			qcom,pc-temp-y5-lut {
				qcom,lut-col-legend = <(-10) 0 10 25 40 50>;
				qcom,lut-row-legend = <10000 9800 9600 9400 9200 9000>, <8800 8600 8400 8200 8000 7800>, <7600 7400 7200 7000 6800 6600>, <6400 6200 6000 5800 5600 5400>, <5200 5000 4800 4600 4400 4200>, <4000 3800 3600 3400 3200 3000>, <2800 2600 2400 2200 2000 1800>, <1600 1400 1200 1000 900 800>, <700 600 500 400 300 200>, <100 0>;
				qcom,lut-data = <12721 12574 11714 21429 17849 17326>, <12803 12771 12744 21468 18570 18483>, <12973 12973 13871 21399 19027 19206>, <13189 13168 14956 21254 19275 19579>, <13409 13341 15860 21065 19364 19684>, <13589 13478 16444 20864 19346 19604>, <13803 13603 16726 20617 19085 19118>, <14004 13701 16946 20324 18627 18469>, <13953 13633 17394 19990 18109 18219>, <13560 13249 18181 19475 17401 18096>, <13346 13035 18531 18914 17098 17935>, <16692 14826 17047 18303 17681 17409>, <21397 17350 15159 17695 18405 16847>, <21122 17566 15776 17243 18227 16892>, <16716 16573 19036 16876 17214 17278>, <14214 15953 21218 16494 16444 17440>, <14420 15709 21885 15920 16026 16823>, <14750 15451 22333 15481 15750 15991>, <14946 15489 22768 16182 15657 15641>, <15097 15640 23194 18832 15554 15368>, <15146 15708 23409 21213 15661 15417>, <14527 15641 22174 23216 18892 18007>, <13647 15495 20561 24650 22340 20867>, <13316 15058 20391 24959 22589 21330>, <13135 13998 20610 24883 22461 21488>, <13070 13366 20235 24666 22317 21470>, <13208 13127 16260 24207 21653 20938>, <13403 12975 12631 23788 20872 20117>, <13492 13087 12510 23613 20523 18961>, <13645 13475 12782 23492 20220 17437>, <13684 13773 13053 23474 20182 16975>, <13637 13915 13460 23659 20645 17317>, <13575 14033 13893 23911 21325 17927>, <13500 14217 14256 24102 22017 19281>, <13394 14508 14596 24301 22817 21299>, <13316 14686 14738 24426 23538 21921>, <13259 14729 14814 24425 24273 21838>, <13212 14767 14871 24242 24690 21762>, <13186 14838 14910 23570 24550 22305>, <13175 14950 14929 22512 24174 23302>, <13194 15035 14908 21807 23757 23520>, <13269 15017 14837 21333 22982 23259>, <13372 14792 14654 20383 21854 22780>, <13650 13967 14272 19178 20572 21652>, <14000 13924 14708 18853 19751 21581>, <14438 13886 14499 18363 18848 17827>, <14630 18063 14599 18826 18806 16858>, <14803 14875 15139 18676 17866 15998>, <15217 14466 15877 18734 17316 15791>, <15861 15167 16467 19013 17053 15568>, <15548 15750 16499 19379 18533 17169>, <14682 14807 15294 19310 19743 17890>, <14145 13958 14232 19167 20475 18350>, <12246 13816 13790 20861 24035 24284>, <12246 13816 13790 20861 24035 24284>, <12246 13816 13790 20861 24035 24284>;
			};

			qcom,pc-temp-y6-lut {
				qcom,lut-col-legend = <(-10) 0 10 25 40 50>;
				qcom,lut-row-legend = <10000 9800 9600 9400 9200 9000>, <8800 8600 8400 8200 8000 7800>, <7600 7400 7200 7000 6800 6600>, <6400 6200 6000 5800 5600 5400>, <5200 5000 4800 4600 4400 4200>, <4000 3800 3600 3400 3200 3000>, <2800 2600 2400 2200 2000 1800>, <1600 1400 1200 1000 900 800>, <700 600 500 400 300 200>, <100 0>;
				qcom,lut-data = <6615 6079 5529 5123 5046 5030>, <6553 6054 5537 5123 5046 5030>, <6493 6028 5540 5122 5045 5031>, <6438 6001 5538 5121 5045 5031>, <6387 5974 5534 5120 5045 5031>, <6342 5947 5527 5119 5045 5031>, <6301 5918 5517 5119 5046 5031>, <6266 5889 5504 5118 5046 5031>, <6233 5865 5494 5118 5046 5031>, <6201 5843 5484 5118 5047 5032>, <6186 5834 5478 5119 5047 5033>, <6190 5839 5478 5119 5049 5034>, <6194 5846 5477 5121 5051 5035>, <6174 5832 5472 5123 5053 5036>, <6087 5766 5457 5126 5054 5038>, <6035 5722 5449 5130 5057 5040>, <6033 5715 5447 5136 5060 5043>, <6031 5711 5446 5143 5064 5045>, <6028 5702 5439 5149 5070 5050>, <6024 5690 5420 5155 5079 5058>, <6020 5679 5402 5156 5082 5061>, <6014 5672 5385 5137 5072 5055>, <6010 5666 5370 5113 5058 5045>, <6010 5663 5364 5103 5049 5037>, <6013 5661 5360 5097 5040 5028>, <6018 5661 5358 5095 5038 5026>, <6028 5669 5360 5095 5038 5026>, <6042 5684 5364 5096 5039 5026>, <6055 5697 5370 5097 5040 5027>, <6069 5710 5382 5099 5043 5029>, <6085 5725 5395 5101 5046 5031>, <6102 5743 5409 5103 5049 5035>, <6121 5763 5424 5105 5052 5038>, <6140 5785 5442 5108 5053 5040>, <6160 5808 5462 5111 5053 5041>, <6182 5832 5484 5114 5053 5041>, <6205 5855 5508 5118 5050 5035>, <6231 5880 5534 5121 5047 5030>, <6261 5909 5562 5123 5047 5031>, <6297 5941 5593 5126 5048 5035>, <6334 5973 5627 5130 5051 5039>, <6372 6002 5667 5135 5055 5044>, <6414 6034 5714 5141 5054 5042>, <6470 6071 5767 5146 5049 5032>, <6529 6121 5816 5155 5050 5033>, <6526 6133 5808 5159 5057 5043>, <6575 6177 5860 5175 5068 5055>, <6632 6220 5906 5191 5079 5067>, <6692 6272 5953 5210 5091 5077>, <6769 6321 5999 5221 5091 5072>, <6846 6374 6041 5211 5071 5050>, <6958 6432 6098 5221 5069 5049>, <7145 6543 6232 5271 5081 5056>, <7921 6727 6391 5340 5104 5078>, <7921 6727 6391 5340 5104 5078>, <7921 6727 6391 5340 5104 5078>;
			};
		};

		qcom,3840738_Xiaomi_F10_Sunwoda_4000mAH_PM7150_FG {
			qcom,max-voltage-uv = <4400000>;
			qcom,fg-cc-cv-threshold-uv = <4390000>;
			qcom,fastchg-current-ma = <3500>;
			qcom,jeita-fcc-ranges = <0 50 390000 51 100 1170000 101 150 2730000 151 450 3500000 451 580 1950000>;
			qcom,jeita-fv-ranges = <0 50 4400000 51 100 4400000 101 150 4400000 151 450 4400000 451 580 4100000>;
			qcom,dynamic-fv-ranges = <0 100 4400000 101 200 4380000 201 300 4360000 301 400 4340000 401 500 4340000>;
			qcom,fg-cc-cv-threshold-mv = <4390>;
			qcom,nom-batt-capacity-mah = <4000>;
			qcom,batt-id-kohm = <68>;
			qcom,battery-beta = <4250>;
			qcom,battery-therm-kohm = <100>;
			qcom,battery-type = "f10_swd";
			qcom,qg-batt-profile-ver = <100>;

			qcom,fcc1-temp-lut {
				qcom,lut-col-legend = <0 10 25 40 50>;
				qcom,lut-data = <3830 3901 3987 4022 4035>;
			};

			qcom,fcc2-temp-lut {
				qcom,lut-col-legend = <(-10) 0 10 25 40 50>;
				qcom,lut-data = <3964 3967 3982 3986 3991 3987>;
			};

			qcom,pc-temp-v1-lut {
				qcom,lut-col-legend = <0 10 25 40 50>;
				qcom,lut-row-legend = <10000 9800 9600 9400 9200>, <9000 8800 8600 8400 8200>, <8000 7800 7600 7400 7200>, <7000 6800 6600 6400 6200>, <6000 5800 5600 5400 5200>, <5000 4800 4600 4400 4200>, <4000 3800 3600 3400 3200>, <3000 2800 2600 2400 2200>, <2000 1800 1600 1400 1200>, <1000 900 800 700 600>, <500 400 300 200 100>, <0>;
				qcom,lut-data = <43639 43742 43833 43859 43868>, <43443 43527 43618 43664 43668>, <43186 43299 43398 43444 43455>, <42923 43062 43172 43220 43236>, <42685 42830 42941 42993 43012>, <42457 42600 42709 42763 42783>, <42233 42371 42477 42533 42555>, <42015 42143 42245 42302 42326>, <41802 41918 42018 42073 42098>, <41595 41698 41793 41845 41870>, <41392 41484 41573 41620 41644>, <41197 41277 41357 41401 41422>, <41016 41082 41146 41187 41203>, <40835 40904 40945 40981 40992>, <40623 40719 40751 40779 40787>, <40370 40496 40558 40582 40589>, <40138 40254 40355 40383 40397>, <39970 40060 40158 40188 40212>, <39828 39918 39987 40011 40036>, <39689 39782 39842 39864 39880>, <39558 39612 39676 39708 39716>, <39420 39418 39436 39487 39499>, <39238 39224 39181 39224 39236>, <39008 39012 39000 39028 39035>, <38822 38825 38862 38891 38901>, <38704 38714 38746 38773 38786>, <38612 38641 38649 38663 38670>, <38539 38574 38563 38562 38559>, <38480 38505 38479 38468 38461>, <38428 38440 38397 38377 38373>, <38379 38378 38324 38296 38293>, <38333 38317 38258 38227 38221>, <38292 38263 38199 38165 38156>, <38254 38216 38145 38106 38091>, <38219 38175 38098 38051 38027>, <38185 38137 38051 37997 37964>, <38153 38105 38008 37943 37902>, <38113 38067 37963 37888 37839>, <38050 38003 37898 37816 37759>, <37967 37908 37806 37720 37656>, <37868 37801 37700 37609 37541>, <37741 37675 37581 37488 37419>, <37599 37533 37444 37353 37284>, <37438 37368 37281 37191 37116>, <37303 37232 37147 37068 36997>, <37223 37152 37067 36988 36933>, <37200 37127 37041 36965 36910>, <37186 37109 37023 36946 36889>, <37168 37088 37008 36923 36865>, <37110 37033 36939 36837 36761>, <36847 36752 36643 36518 36422>, <36378 36289 36184 36057 35960>, <35789 35697 35582 35456 35358>, <34977 34871 34757 34631 34529>, <33685 33560 33449 33321 33215>, <30000 30000 30000 30000 30000>;
			};

			qcom,pc-temp-v2-lut {
				qcom,lut-col-legend = <(-10) 0 10 25 40 50>;
				qcom,lut-row-legend = <10000 9800 9600 9400 9200 9000>, <8800 8600 8400 8200 8000 7800>, <7600 7400 7200 7000 6800 6600>, <6400 6200 6000 5800 5600 5400>, <5200 5000 4800 4600 4400 4200>, <4000 3800 3600 3400 3200 3000>, <2800 2600 2400 2200 2000 1800>, <1600 1400 1200 1000 900 800>, <700 600 500 400 300 200>, <100 0>;
				qcom,lut-data = <43895 43870 43850 43805 43785 43765>, <43543 43557 43579 43544 43530 43513>, <43218 43262 43316 43289 43281 43268>, <42918 42986 43063 43044 43039 43031>, <42640 42730 42820 42808 42804 42801>, <42390 42481 42581 42574 42571 42572>, <42180 42234 42344 42341 42339 42340>, <41987 41993 42110 42109 42108 42107>, <41758 41758 41881 41881 41880 41878>, <41468 41525 41654 41655 41655 41650>, <41238 41309 41434 41432 41433 41426>, <41139 41125 41222 41214 41215 41208>, <41067 40956 41017 41000 41000 40993>, <40909 40764 40815 40796 40795 40787>, <40503 40547 40615 40600 40596 40585>, <40074 40315 40417 40405 40402 40390>, <39779 40055 40218 40201 40205 40200>, <39529 39782 40018 39999 40013 40018>, <39340 39555 39806 39825 39840 39846>, <39206 39367 39578 39682 39689 39691>, <39072 39193 39356 39524 39523 39521>, <38874 39022 39151 39293 39296 39296>, <38641 38858 38959 39031 39048 39049>, <38480 38700 38794 38835 38855 38858>, <38375 38545 38650 38683 38700 38707>, <38293 38402 38522 38554 38568 38576>, <38224 38274 38410 38440 38451 38456>, <38165 38159 38308 38338 38348 38349>, <38108 38081 38211 38245 38255 38254>, <38051 38029 38112 38159 38171 38169>, <37997 37987 38027 38081 38094 38092>, <37947 37942 37960 38009 38025 38022>, <37900 37899 37906 37942 37960 37956>, <37852 37858 37858 37879 37892 37885>, <37802 37820 37819 37823 37820 37808>, <37750 37781 37780 37766 37742 37721>, <37694 37738 37740 37703 37651 37619>, <37635 37693 37698 37636 37553 37505>, <37565 37636 37643 37562 37462 37406>, <37481 37558 37567 37480 37380 37325>, <37387 37463 37475 37386 37291 37240>, <37288 37354 37358 37275 37183 37130>, <37184 37228 37218 37150 37066 37008>, <37096 37087 37069 37019 36944 36886>, <37022 36958 36952 36920 36853 36801>, <36952 36884 36889 36871 36812 36760>, <36907 36853 36859 36855 36800 36747>, <36856 36823 36832 36838 36781 36727>, <36779 36776 36787 36801 36742 36684>, <36655 36675 36679 36690 36594 36503>, <36393 36432 36380 36356 36212 36108>, <35945 35966 35872 35838 35682 35573>, <35300 35324 35202 35174 34988 34869>, <34375 34430 34278 34271 34045 33932>, <32935 33097 32975 32791 32630 32448>, <27703 28392 27520 27513 27500 27362>;
			};

			qcom,pc-temp-z1-lut {
				qcom,lut-col-legend = <0 10 25 40 50>;
				qcom,lut-row-legend = <10000 9800 9600 9400 9200>, <9000 8800 8600 8400 8200>, <8000 7800 7600 7400 7200>, <7000 6800 6600 6400 6200>, <6000 5800 5600 5400 5200>, <5000 4800 4600 4400 4200>, <4000 3800 3600 3400 3200>, <3000 2800 2600 2400 2200>, <2000 1800 1600 1400 1200>, <1000 900 800 700 600>, <500 400 300 200 100>, <0>;
				qcom,lut-data = <13088 12531 11917 11542 11397>, <13133 12581 11958 11594 11459>, <13170 12587 11982 11610 11479>, <13190 12580 11982 11613 11487>, <13188 12572 11971 11612 11486>, <13182 12560 11959 11610 11485>, <13172 12548 11947 11606 11484>, <13140 12543 11936 11600 11483>, <13107 12535 11927 11598 11482>, <13097 12525 11920 11597 11480>, <13092 12510 11916 11597 11478>, <13088 12491 11914 11595 11477>, <13081 12475 11913 11594 11476>, <13070 12459 11911 11592 11476>, <13052 12449 11910 11591 11476>, <13009 12446 11908 11590 11475>, <12979 12446 11905 11588 11475>, <12977 12446 11901 11587 11477>, <12979 12450 11901 11587 11479>, <12980 12456 11903 11588 11479>, <12984 12457 11906 11590 11480>, <12991 12459 11909 11590 11483>, <13003 12459 11914 11591 11486>, <13024 12461 11917 11592 11487>, <13034 12463 11919 11594 11485>, <13026 12467 11922 11597 11484>, <13013 12471 11928 11600 11486>, <13011 12473 11935 11604 11491>, <13021 12477 11940 11608 11495>, <13033 12481 11945 11615 11498>, <13046 12482 11949 11620 11501>, <13064 12482 11956 11624 11505>, <13071 12482 11963 11627 11510>, <13059 12490 11968 11631 11515>, <13046 12504 11974 11637 11520>, <13045 12512 11979 11643 11526>, <13049 12516 11984 11648 11531>, <13054 12518 11989 11653 11536>, <13059 12522 11996 11658 11540>, <13065 12528 12006 11665 11543>, <13073 12532 12016 11671 11546>, <13092 12534 12026 11675 11549>, <13106 12539 12033 11678 11553>, <13126 12550 12035 11684 11557>, <13107 12573 12044 11692 11562>, <13101 12566 12050 11696 11564>, <13094 12583 12059 11696 11561>, <13100 12577 12054 11694 11563>, <13121 12564 12050 11698 11566>, <13128 12572 12057 11705 11572>, <13139 12610 12070 11713 11580>, <13125 12583 12082 11719 11586>, <13164 12615 12092 11733 11597>, <13201 12636 12114 11749 11611>, <13201 12636 12114 11749 11611>, <13201 12636 12114 11749 11611>;
			};

			qcom,pc-temp-z2-lut {
				qcom,lut-col-legend = <0 10 25 40 50>;
				qcom,lut-row-legend = <10000 9800 9600 9400 9200>, <9000 8800 8600 8400 8200>, <8000 7800 7600 7400 7200>, <7000 6800 6600 6400 6200>, <6000 5800 5600 5400 5200>, <5000 4800 4600 4400 4200>, <4000 3800 3600 3400 3200>, <3000 2800 2600 2400 2200>, <2000 1800 1600 1400 1200>, <1000 900 800 700 600>, <500 400 300 200 100>, <0>;
				qcom,lut-data = <10298 10226 10016 10004 9896>, <12902 10726 10100 10009 9937>, <11279 10665 10152 10040 9996>, <10100 10464 10155 10062 10029>, <10052 10405 10141 10073 10047>, <10039 10484 10125 10079 10059>, <10025 10558 10106 10067 10046>, <10006 10478 10087 10044 10006>, <9993 10222 10076 10030 9980>, <9989 10063 10067 10023 9970>, <9988 10062 10063 10016 9962>, <9989 10063 10066 9985 9952>, <10022 10067 10073 9920 9932>, <10066 10090 10210 9896 9920>, <10068 10110 10727 9917 9919>, <10025 10112 11028 9937 9919>, <9992 10114 11030 9932 9920>, <10006 10116 10999 9916 9919>, <10040 10128 10848 9911 9922>, <10063 10144 10370 9917 9932>, <10078 10161 10099 9928 9954>, <10088 10180 10160 10020 10044>, <10094 10187 10244 10213 10245>, <10098 10180 10243 10263 10319>, <10100 10173 10178 10130 10188>, <10100 10172 10140 10012 10052>, <10100 10174 10154 10082 10109>, <10100 10177 10177 10237 10281>, <10106 10178 10190 10277 10334>, <10113 10179 10201 10209 10200>, <10118 10182 10205 10128 10039>, <10124 10191 10188 10076 9948>, <10131 10200 10162 10032 9877>, <10141 10207 10162 9995 9863>, <10151 10212 10183 9959 9888>, <10162 10218 10200 9939 9920>, <10174 10223 10207 9962 9952>, <10187 10230 10215 10013 9989>, <10200 10244 10234 10045 10013>, <10213 10266 10277 10065 10029>, <10225 10282 10310 10081 10041>, <10234 10291 10322 10091 10051>, <10250 10302 10326 10104 10060>, <10287 10324 10326 10164 10083>, <10515 10457 10354 10159 10072>, <10566 10498 10320 10102 10030>, <10558 10502 10340 10136 10051>, <10544 10490 10313 10124 10032>, <10527 10509 10310 10148 10087>, <10615 10575 10420 10185 10076>, <10633 10617 10340 10061 9966>, <10559 10547 10299 9957 9864>, <10341 10585 10269 9927 9830>, <10223 10502 10191 9907 9781>, <10223 10502 10191 9907 9781>, <10223 10502 10191 9907 9781>;
			};

			qcom,pc-temp-z3-lut {
				qcom,lut-col-legend = <0 10 25 40 50>;
				qcom,lut-row-legend = <10000 9800 9600 9400 9200>, <9000 8800 8600 8400 8200>, <8000 7800 7600 7400 7200>, <7000 6800 6600 6400 6200>, <6000 5800 5600 5400 5200>, <5000 4800 4600 4400 4200>, <4000 3800 3600 3400 3200>, <3000 2800 2600 2400 2200>, <2000 1800 1600 1400 1200>, <1000 900 800 700 600>, <500 400 300 200 100>, <0>;
				qcom,lut-data = <19698 19460 19373 19365 19351>, <19401 19519 19429 19367 19358>, <19605 19548 19467 19401 19388>, <19765 19588 19481 19423 19410>, <19786 19614 19489 19433 19420>, <19797 19639 19493 19439 19427>, <19799 19666 19494 19442 19429>, <19792 19665 19496 19443 19431>, <19782 19636 19495 19443 19432>, <19773 19612 19491 19441 19428>, <19762 19607 19486 19436 19423>, <19757 19603 19477 19429 19418>, <19765 19595 19469 19419 19415>, <19776 19574 19473 19414 19411>, <19777 19558 19494 19412 19408>, <19767 19564 19505 19411 19404>, <19754 19577 19502 19409 19400>, <19734 19580 19496 19408 19396>, <19710 19561 19483 19406 19391>, <19699 19543 19453 19396 19383>, <19696 19550 19437 19387 19377>, <19694 19575 19447 19393 19381>, <19705 19587 19460 19406 19392>, <19741 19584 19459 19409 19395>, <19761 19580 19442 19389 19380>, <19756 19575 19433 19371 19364>, <19745 19568 19433 19383 19383>, <19734 19564 19435 19410 19432>, <19724 19563 19441 19427 19449>, <19713 19564 19458 19438 19442>, <19704 19565 19469 19444 19432>, <19695 19570 19470 19439 19423>, <19687 19573 19469 19429 19413>, <19680 19572 19467 19419 19403>, <19675 19568 19460 19409 19394>, <19671 19563 19453 19401 19386>, <19669 19555 19447 19394 19381>, <19666 19548 19441 19389 19377>, <19660 19544 19438 19386 19375>, <19653 19541 19437 19385 19374>, <19646 19537 19435 19384 19373>, <19640 19531 19430 19386 19376>, <19632 19525 19425 19390 19383>, <19613 19517 19425 19395 19392>, <19546 19483 19416 19388 19391>, <19510 19464 19391 19373 19371>, <19483 19461 19391 19355 19355>, <19425 19456 19392 19351 19352>, <19351 19457 19373 19352 19337>, <19348 19425 19358 19349 19348>, <19398 19427 19391 19386 19379>, <19401 19440 19402 19391 19383>, <19343 19362 19412 19393 19383>, <19338 19360 19402 19381 19382>, <19338 19360 19402 19381 19382>, <19338 19360 19402 19381 19382>;
			};

			qcom,pc-temp-z4-lut {
				qcom,lut-col-legend = <0 10 25 40 50>;
				qcom,lut-row-legend = <10000 9800 9600 9400 9200>, <9000 8800 8600 8400 8200>, <8000 7800 7600 7400 7200>, <7000 6800 6600 6400 6200>, <6000 5800 5600 5400 5200>, <5000 4800 4600 4400 4200>, <4000 3800 3600 3400 3200>, <3000 2800 2600 2400 2200>, <2000 1800 1600 1400 1200>, <1000 900 800 700 600>, <500 400 300 200 100>, <0>;
				qcom,lut-data = <15404 15346 15034 14923 14880>, <15754 15332 15033 14931 14914>, <15611 15285 15027 14928 14907>, <15449 15174 15008 14921 14896>, <15326 15062 14951 14893 14875>, <15215 14951 14899 14856 14846>, <15131 14861 14863 14829 14821>, <15068 14845 14831 14805 14797>, <15019 14844 14803 14784 14779>, <14983 14842 14778 14765 14765>, <14956 14827 14760 14751 14754>, <14924 14801 14753 14748 14748>, <14862 14784 14746 14746 14744>, <14803 14772 14724 14742 14740>, <14795 14766 14677 14732 14734>, <14812 14765 14651 14721 14728>, <14825 14766 14650 14716 14723>, <14822 14764 14650 14714 14719>, <14812 14754 14654 14709 14715>, <14802 14744 14669 14699 14707>, <14787 14745 14691 14692 14700>, <14775 14752 14743 14719 14723>, <14785 14764 14807 14789 14793>, <14824 14820 14841 14831 14832>, <14852 14880 14864 14854 14846>, <14858 14884 14873 14866 14854>, <14863 14867 14862 14846 14827>, <14862 14848 14839 14797 14758>, <14851 14829 14814 14763 14727>, <14836 14809 14782 14739 14722>, <14825 14791 14756 14723 14718>, <14813 14773 14740 14714 14712>, <14802 14760 14728 14709 14706>, <14792 14753 14722 14706 14703>, <14782 14748 14718 14706 14700>, <14773 14745 14716 14705 14698>, <14763 14742 14715 14703 14697>, <14758 14741 14714 14701 14696>, <14760 14744 14716 14703 14698>, <14762 14750 14724 14715 14714>, <14763 14753 14730 14724 14727>, <14761 14751 14728 14720 14720>, <14759 14748 14725 14713 14711>, <14754 14742 14723 14712 14712>, <14729 14718 14706 14701 14698>, <14729 14703 14702 14686 14678>, <14752 14695 14688 14691 14678>, <14810 14691 14672 14675 14660>, <14884 14682 14675 14650 14649>, <14882 14714 14693 14652 14636>, <14833 14726 14689 14665 14671>, <14842 14722 14686 14673 14681>, <14917 14813 14678 14679 14689>, <14931 14816 14695 14695 14694>, <14931 14816 14695 14695 14694>, <14931 14816 14695 14695 14694>;
			};

			qcom,pc-temp-z5-lut {
				qcom,lut-col-legend = <0 10 25 40 50>;
				qcom,lut-row-legend = <10000 9800 9600 9400 9200>, <9000 8800 8600 8400 8200>, <8000 7800 7600 7400 7200>, <7000 6800 6600 6400 6200>, <6000 5800 5600 5400 5200>, <5000 4800 4600 4400 4200>, <4000 3800 3600 3400 3200>, <3000 2800 2600 2400 2200>, <2000 1800 1600 1400 1200>, <1000 900 800 700 600>, <500 400 300 200 100>, <0>;
				qcom,lut-data = <13374 12310 12733 14082 14017>, <11333 13381 14710 14050 14313>, <12978 13902 16154 15980 16270>, <14542 14809 16863 17355 17924>, <15211 15603 17270 18010 18784>, <15699 17130 17707 18532 19457>, <16017 18918 18278 19059 20085>, <16272 19204 18919 19558 20657>, <16426 18912 19694 20170 21213>, <16480 18707 20626 21174 21819>, <16655 19207 21121 21927 22375>, <16956 20098 21242 21650 22736>, <18130 20296 21353 20791 23037>, <19772 19946 23715 20515 23307>, <20884 19652 32353 21343 23908>, <21850 20965 37442 22531 24636>, <22378 23792 37192 23622 24986>, <21858 24625 36041 24728 25320>, <20724 22998 33868 25184 25676>, <20344 21404 28619 25287 26153>, <21189 25507 25709 25399 26805>, <22957 37694 30185 26923 27875>, <28882 43197 36308 30044 29382>, <43056 39484 35238 30341 29549>, <50759 33702 26329 23046 23057>, <46668 29529 20285 16641 16508>, <39370 25555 19040 16974 18462>, <34684 23726 18352 18504 24585>, <31416 23645 18711 20549 27149>, <29160 23651 21085 24332 27506>, <27904 24197 23745 27100 27663>, <27011 27079 26209 27399 27468>, <26760 29983 28546 27535 26999>, <26842 31709 30055 27540 26838>, <27014 33043 31253 27279 27069>, <27586 33235 31752 27077 27332>, <29114 32129 31406 27052 27563>, <30077 30884 30660 26970 27875>, <30130 30332 29766 26692 27731>, <30036 29924 28471 25444 25702>, <29699 29279 26911 24188 23987>, <28774 27497 24470 23451 24050>, <28396 26347 22846 23048 24663>, <27628 26036 22996 24469 28658>, <27491 26498 23145 23680 29794>, <23369 25476 19888 20007 21882>, <21377 25294 20518 16788 17652>, <17409 24403 22055 17334 18820>, <12662 25668 18737 20523 18880>, <12859 18518 16192 19097 24482>, <14848 18523 18635 23260 23678>, <15035 18900 19370 21258 20434>, <12343 13215 20482 19427 17970>, <12074 13019 17769 15808 15755>, <12074 13019 17769 15808 15755>, <12074 13019 17769 15808 15755>;
			};

			qcom,pc-temp-z6-lut {
				qcom,lut-col-legend = <0 10 25 40 50>;
				qcom,lut-row-legend = <10000 9800 9600 9400 9200>, <9000 8800 8600 8400 8200>, <8000 7800 7600 7400 7200>, <7000 6800 6600 6400 6200>, <6000 5800 5600 5400 5200>, <5000 4800 4600 4400 4200>, <4000 3800 3600 3400 3200>, <3000 2800 2600 2400 2200>, <2000 1800 1600 1400 1200>, <1000 900 800 700 600>, <500 400 300 200 100>, <0>;
				qcom,lut-data = <15803 15287 14836 14703 14655>, <15757 15296 14871 14719 14687>, <15737 15279 14888 14741 14704>, <15713 15229 14884 14748 14711>, <15658 15178 14862 14741 14707>, <15578 15138 14839 14729 14699>, <15513 15099 14823 14719 14691>, <15461 15069 14807 14709 14682>, <15417 15044 14792 14700 14673>, <15383 15022 14777 14690 14665>, <15355 15004 14765 14682 14657>, <15327 14988 14757 14675 14652>, <15291 14969 14749 14669 14648>, <15258 14946 14742 14663 14643>, <15239 14931 14735 14657 14639>, <15229 14933 14729 14652 14634>, <15219 14936 14725 14648 14629>, <15205 14937 14722 14646 14625>, <15191 14923 14717 14642 14620>, <15182 14910 14709 14632 14612>, <15177 14913 14705 14625 14606>, <15174 14928 14731 14641 14619>, <15184 14946 14770 14681 14657>, <15223 14971 14780 14694 14672>, <15246 14993 14784 14693 14670>, <15246 14994 14785 14693 14667>, <15244 14985 14781 14691 14665>, <15241 14976 14773 14686 14662>, <15233 14969 14768 14682 14659>, <15223 14962 14764 14678 14654>, <15215 14958 14760 14674 14648>, <15207 14954 14755 14668 14642>, <15200 14952 14751 14662 14635>, <15193 14949 14747 14656 14628>, <15188 14946 14742 14651 14623>, <15186 14944 14739 14646 14618>, <15186 14941 14736 14642 14615>, <15185 14940 14734 14638 14612>, <15187 14942 14735 14638 14612>, <15191 14947 14740 14643 14617>, <15194 14949 14743 14647 14622>, <15197 14950 14741 14647 14622>, <15198 14950 14740 14647 14622>, <15197 14950 14740 14650 14628>, <15169 14934 14731 14643 14623>, <15155 14919 14718 14629 14603>, <15151 14914 14712 14622 14595>, <15145 14911 14706 14612 14586>, <15141 14909 14698 14602 14572>, <15144 14909 14699 14602 14574>, <15156 14923 14718 14630 14608>, <15169 14932 14726 14639 14617>, <15181 14939 14731 14645 14624>, <15204 14951 14738 14650 14629>, <15204 14951 14738 14650 14629>, <15204 14951 14738 14650 14629>;
			};

			qcom,pc-temp-y1-lut {
				qcom,lut-col-legend = <(-10) 0 10 25 40 50>;
				qcom,lut-row-legend = <10000 9800 9600 9400 9200 9000>, <8800 8600 8400 8200 8000 7800>, <7600 7400 7200 7000 6800 6600>, <6400 6200 6000 5800 5600 5400>, <5200 5000 4800 4600 4400 4200>, <4000 3800 3600 3400 3200 3000>, <2800 2600 2400 2200 2000 1800>, <1600 1400 1200 1000 900 800>, <700 600 500 400 300 200>, <100 0>;
				qcom,lut-data = <6499 5973 5732 5440 5219 5136>, <6504 6009 5757 5435 5217 5135>, <6506 6036 5772 5430 5215 5134>, <6506 6055 5780 5424 5212 5133>, <6504 6066 5783 5420 5210 5132>, <6501 6070 5783 5416 5208 5131>, <6491 6061 5775 5413 5206 5131>, <6479 6045 5760 5410 5204 5130>, <6476 6040 5756 5409 5202 5129>, <6476 6041 5758 5408 5200 5127>, <6477 6043 5759 5408 5198 5126>, <6493 6049 5754 5405 5198 5126>, <6524 6058 5747 5401 5197 5126>, <6534 6062 5745 5400 5197 5126>, <6533 6061 5750 5401 5195 5126>, <6530 6059 5754 5402 5195 5125>, <6518 6062 5754 5403 5195 5125>, <6500 6068 5755 5403 5196 5126>, <6494 6072 5758 5403 5196 5126>, <6504 6075 5768 5403 5196 5126>, <6514 6077 5776 5404 5196 5126>, <6516 6076 5773 5406 5196 5126>, <6521 6075 5767 5411 5198 5127>, <6517 6074 5765 5415 5201 5127>, <6494 6075 5772 5420 5203 5129>, <6474 6076 5777 5424 5206 5131>, <6484 6072 5775 5427 5209 5133>, <6510 6064 5772 5431 5213 5136>, <6519 6060 5773 5435 5215 5138>, <6508 6057 5776 5442 5217 5142>, <6492 6054 5780 5449 5219 5146>, <6477 6057 5786 5456 5223 5149>, <6460 6068 5792 5462 5229 5151>, <6451 6074 5794 5466 5234 5153>, <6449 6071 5794 5471 5237 5156>, <6448 6066 5793 5475 5240 5158>, <6453 6063 5794 5480 5243 5160>, <6463 6061 5796 5485 5245 5163>, <6466 6058 5797 5488 5247 5164>, <6458 6051 5802 5488 5248 5165>, <6453 6046 5808 5490 5250 5166>, <6460 6050 5815 5492 5252 5167>, <6470 6059 5823 5496 5254 5169>, <6459 6055 5817 5506 5261 5173>, <6439 6051 5811 5519 5268 5178>, <6477 6057 5822 5527 5268 5179>, <6480 6077 5821 5527 5267 5178>, <6474 6097 5818 5522 5267 5177>, <6519 6070 5819 5524 5266 5181>, <6500 6070 5825 5520 5268 5181>, <6499 6076 5831 5526 5271 5184>, <6487 6077 5820 5548 5278 5189>, <6539 6105 5834 5562 5287 5197>, <6573 6124 5867 5569 5299 5208>, <6573 6124 5867 5569 5299 5208>, <6573 6124 5867 5569 5299 5208>;
			};

			qcom,pc-temp-y2-lut {
				qcom,lut-col-legend = <(-10) 0 10 25 40 50>;
				qcom,lut-row-legend = <10000 9800 9600 9400 9200 9000>, <8800 8600 8400 8200 8000 7800>, <7600 7400 7200 7000 6800 6600>, <6400 6200 6000 5800 5600 5400>, <5200 5000 4800 4600 4400 4200>, <4000 3800 3600 3400 3200 3000>, <2800 2600 2400 2200 2000 1800>, <1600 1400 1200 1000 900 800>, <700 600 500 400 300 200>, <100 0>;
				qcom,lut-data = <10135 10021 10461 10935 10658 10684>, <10099 10085 10477 10879 10652 10677>, <10091 10139 10488 10807 10638 10666>, <10105 10179 10494 10733 10620 10653>, <10136 10205 10497 10675 10606 10639>, <10178 10214 10498 10649 10599 10624>, <10237 10200 10494 10650 10590 10608>, <10313 10176 10488 10658 10575 10590>, <10386 10185 10488 10660 10566 10570>, <10465 10288 10498 10658 10559 10544>, <10522 10383 10510 10658 10552 10524>, <10545 10413 10518 10663 10532 10512>, <10564 10436 10527 10670 10508 10502>, <10615 10468 10557 10681 10509 10503>, <10796 10531 10661 10698 10548 10527>, <10932 10607 10751 10722 10598 10545>, <10591 10681 10780 10765 10649 10539>, <9893 10762 10799 10827 10709 10529>, <9684 10862 10822 10893 10772 10557>, <9683 11014 10848 10979 10851 10722>, <9682 11114 10873 11028 10893 10840>, <9679 11044 10895 10997 10846 10807>, <9674 10880 10917 10941 10767 10748>, <9671 10816 10949 10931 10747 10729>, <9670 10808 10997 10957 10757 10724>, <9669 10802 11044 10986 10769 10722>, <9668 10699 11084 11005 10790 10732>, <9667 10425 11119 11028 10822 10754>, <9667 10253 11124 11058 10847 10778>, <9666 9957 11102 11119 10874 10806>, <9665 9709 11084 11174 10902 10831>, <9664 9694 11087 11204 10943 10846>, <9664 9691 11092 11225 10989 10859>, <9663 9687 11093 11233 11003 10873>, <9663 9683 11081 11229 11014 10907>, <9663 9679 11062 11217 11015 10933>, <9663 9676 11043 11192 10978 10905>, <9662 9672 11019 11155 10925 10848>, <9662 9670 10994 11130 10909 10830>, <9661 9668 10965 11109 10905 10835>, <9661 9666 10928 11091 10901 10839>, <9661 9664 10866 11077 10893 10815>, <9660 9663 10769 11056 10876 10756>, <9660 9661 10677 11015 10822 10682>, <9660 9660 10540 10945 10726 10588>, <9659 9659 10346 10917 10677 10555>, <9659 9659 10162 10918 10685 10547>, <9659 9659 10050 10922 10705 10529>, <9658 9658 9990 10928 10756 10568>, <9658 9657 10126 10946 10734 10573>, <9657 9657 9853 10893 10661 10540>, <9656 9656 9719 10818 10615 10474>, <9655 9656 9685 10765 10541 10393>, <9653 9655 9672 10715 10454 10282>, <9653 9655 9672 10715 10454 10282>, <9653 9655 9672 10715 10454 10282>;
			};

			qcom,pc-temp-y3-lut {
				qcom,lut-col-legend = <(-10) 0 10 25 40 50>;
				qcom,lut-row-legend = <10000 9800 9600 9400 9200 9000>, <8800 8600 8400 8200 8000 7800>, <7600 7400 7200 7000 6800 6600>, <6400 6200 6000 5800 5600 5400>, <5200 5000 4800 4600 4400 4200>, <4000 3800 3600 3400 3200 3000>, <2800 2600 2400 2200 2000 1800>, <1600 1400 1200 1000 900 800>, <700 600 500 400 300 200>, <100 0>;
				qcom,lut-data = <13974 13596 13379 13306 13292 13284>, <13927 13594 13380 13304 13290 13285>, <13883 13591 13382 13302 13289 13286>, <13847 13588 13383 13302 13288 13287>, <13821 13584 13384 13302 13288 13288>, <13811 13580 13385 13303 13288 13288>, <13821 13572 13386 13304 13289 13289>, <13837 13563 13386 13305 13291 13289>, <13817 13564 13386 13306 13292 13289>, <13659 13582 13384 13307 13293 13290>, <13540 13596 13383 13307 13294 13291>, <13543 13548 13385 13308 13296 13292>, <13554 13459 13389 13310 13298 13293>, <13556 13440 13388 13312 13300 13295>, <13547 13469 13374 13315 13301 13296>, <13535 13491 13364 13317 13302 13297>, <13509 13481 13367 13315 13303 13298>, <13474 13455 13370 13312 13304 13298>, <13467 13431 13370 13311 13303 13298>, <13487 13406 13363 13313 13302 13299>, <13505 13384 13355 13314 13300 13299>, <13497 13367 13348 13311 13296 13294>, <13475 13354 13342 13305 13290 13287>, <13465 13351 13337 13301 13289 13285>, <13463 13355 13332 13300 13288 13286>, <13463 13359 13328 13298 13288 13286>, <13474 13355 13324 13297 13287 13285>, <13501 13345 13321 13296 13286 13284>, <13525 13337 13320 13296 13286 13284>, <13542 13329 13318 13296 13285 13285>, <13560 13322 13317 13296 13285 13286>, <13582 13328 13317 13295 13286 13286>, <13608 13347 13318 13295 13287 13286>, <13633 13365 13318 13295 13288 13286>, <13656 13380 13318 13295 13289 13287>, <13679 13395 13319 13295 13289 13287>, <13704 13413 13320 13295 13288 13287>, <13732 13434 13322 13295 13287 13286>, <13762 13457 13323 13296 13287 13286>, <13794 13481 13324 13296 13288 13288>, <13826 13509 13325 13296 13289 13290>, <13856 13546 13325 13296 13290 13289>, <13885 13594 13324 13296 13290 13288>, <13922 13645 13327 13295 13288 13288>, <13972 13705 13331 13297 13289 13289>, <14022 13762 13334 13302 13296 13294>, <13998 13748 13331 13305 13299 13296>, <14050 13804 13338 13311 13301 13298>, <14108 13859 13350 13315 13303 13299>, <14176 13919 13365 13316 13299 13295>, <14241 13968 13374 13310 13296 13295>, <14342 14029 13397 13312 13299 13298>, <14507 14142 13438 13319 13305 13304>, <14903 14279 13504 13333 13316 13315>, <14903 14279 13504 13333 13316 13315>, <14903 14279 13504 13333 13316 13315>;
			};

			qcom,pc-temp-y4-lut {
				qcom,lut-col-legend = <(-10) 0 10 25 40 50>;
				qcom,lut-row-legend = <10000 9800 9600 9400 9200 9000>, <8800 8600 8400 8200 8000 7800>, <7600 7400 7200 7000 6800 6600>, <6400 6200 6000 5800 5600 5400>, <5200 5000 4800 4600 4400 4200>, <4000 3800 3600 3400 3200 3000>, <2800 2600 2400 2200 2000 1800>, <1600 1400 1200 1000 900 800>, <700 600 500 400 300 200>, <100 0>;
				qcom,lut-data = <17292 16938 16636 16487 16470 16482>, <17367 16945 16649 16488 16472 16481>, <17400 16955 16657 16490 16473 16480>, <17402 16966 16663 16493 16474 16479>, <17380 16976 16665 16495 16475 16479>, <17346 16981 16666 16496 16476 16478>, <17258 16983 16663 16497 16476 16478>, <17144 16985 16658 16497 16476 16478>, <17151 16974 16657 16499 16477 16479>, <17372 16903 16659 16505 16479 16479>, <17549 16851 16662 16511 16482 16480>, <17573 16979 16666 16515 16484 16482>, <17586 17214 16672 16521 16487 16484>, <17550 17263 16691 16528 16491 16486>, <17250 17158 16766 16540 16498 16490>, <17008 17040 16818 16554 16505 16495>, <17016 16964 16812 16572 16512 16501>, <17042 16902 16795 16592 16520 16509>, <17045 16874 16769 16613 16537 16523>, <16988 16864 16716 16639 16575 16552>, <16910 16854 16664 16654 16599 16571>, <16828 16832 16626 16612 16572 16551>, <16743 16796 16595 16533 16520 16513>, <16719 16750 16579 16499 16493 16492>, <16726 16668 16570 16486 16477 16480>, <16732 16602 16565 16480 16470 16474>, <16728 16586 16563 16482 16471 16474>, <16717 16581 16562 16487 16475 16475>, <16713 16587 16557 16492 16480 16477>, <16716 16621 16539 16497 16491 16484>, <16721 16652 16524 16502 16502 16492>, <16723 16655 16524 16508 16511 16505>, <16724 16654 16526 16514 16518 16518>, <16726 16655 16530 16517 16519 16522>, <16730 16662 16543 16519 16518 16522>, <16735 16671 16558 16520 16515 16522>, <16740 16681 16571 16516 16503 16510>, <16745 16692 16584 16509 16485 16487>, <16747 16696 16589 16505 16481 16482>, <16740 16695 16590 16504 16485 16490>, <16731 16694 16591 16504 16488 16497>, <16726 16689 16590 16504 16486 16494>, <16723 16677 16586 16504 16481 16485>, <16726 16663 16578 16502 16470 16466>, <16739 16655 16576 16503 16468 16463>, <16759 16655 16582 16505 16494 16511>, <16750 16655 16597 16515 16525 16545>, <16772 16675 16623 16542 16560 16581>, <16800 16707 16654 16576 16588 16604>, <16817 16740 16673 16582 16562 16551>, <16811 16742 16671 16528 16493 16493>, <16786 16722 16665 16523 16488 16490>, <16787 16727 16688 16546 16496 16493>, <16899 16756 16740 16594 16542 16545>, <16899 16756 16740 16594 16542 16545>, <16899 16756 16740 16594 16542 16545>;
			};

			qcom,pc-temp-y5-lut {
				qcom,lut-col-legend = <(-10) 0 10 25 40 50>;
				qcom,lut-row-legend = <10000 9800 9600 9400 9200 9000>, <8800 8600 8400 8200 8000 7800>, <7600 7400 7200 7000 6800 6600>, <6400 6200 6000 5800 5600 5400>, <5200 5000 4800 4600 4400 4200>, <4000 3800 3600 3400 3200 3000>, <2800 2600 2400 2200 2000 1800>, <1600 1400 1200 1000 900 800>, <700 600 500 400 300 200>, <100 0>;
				qcom,lut-data = <14230 12035 14717 18923 21990 17494>, <12932 12428 15022 18564 20707 18657>, <12349 12911 15377 17987 19354 19364>, <12331 13387 15732 17353 18105 19729>, <12728 13757 16034 16823 17135 19865>, <13391 13923 16232 16560 16621 19885>, <15459 13883 16356 16444 16552 19539>, <18252 13802 16444 16253 16642 18825>, <18338 13977 16409 15975 16640 18187>, <14707 15134 16089 15461 16444 17516>, <11979 15986 15719 14988 16295 17056>, <13250 14923 15314 14683 16383 16929>, <16139 12966 14856 14446 16487 16867>, <18385 12945 14615 14313 16288 16676>, <20468 16637 14463 14205 15764 16356>, <21643 19583 14394 14138 15321 15972>, <19461 18861 16234 14042 15079 15420>, <15022 17291 19546 13942 14896 14863>, <14009 16789 20518 14354 14864 14762>, <16803 16749 20570 16799 14987 14861>, <19239 16744 20480 19216 15284 15034>, <18212 17028 20243 20547 16764 15930>, <15459 17911 19875 21518 18991 17580>, <13733 19365 19484 21611 19866 18863>, <12720 23296 18974 20945 20112 20077>, <12160 26434 18670 20123 20030 20735>, <12293 23791 18933 19274 18930 19537>, <12667 17008 19529 18404 17263 17283>, <12802 13833 19944 18157 16469 16466>, <12752 13032 20483 18385 15904 16228>, <12702 12652 20805 18569 15613 16129>, <12793 12712 20393 18709 16131 16219>, <13095 12959 19623 19044 17299 16493>, <13341 13226 19308 19252 18399 17046>, <13548 13507 18872 19713 19668 18698>, <13740 13808 18473 20039 20362 20052>, <13906 14154 18469 19987 20082 20310>, <14130 14550 18602 19823 19587 20454>, <14259 14712 18557 19519 19393 20737>, <14256 14537 18371 18661 19276 21348>, <14164 14305 18144 17854 19258 22046>, <13836 14307 17547 17458 20149 23138>, <13240 14410 16729 17045 21238 24067>, <13015 14139 16783 16260 18827 21403>, <12966 13717 16771 16036 16528 18163>, <13220 13972 15929 16543 16569 15610>, <13236 13830 14410 16911 16151 15037>, <13375 13993 14285 17520 15825 14672>, <13477 13926 14471 17640 15870 14663>, <14073 14149 15806 18014 15543 14707>, <13997 14427 14931 18212 16930 16093>, <13804 14128 14566 18854 17572 16420>, <13507 13988 14538 19667 18705 17374>, <13029 14263 15107 22152 23922 24346>, <13029 14263 15107 22152 23922 24346>, <13029 14263 15107 22152 23922 24346>;
			};

			qcom,pc-temp-y6-lut {
				qcom,lut-col-legend = <(-10) 0 10 25 40 50>;
				qcom,lut-row-legend = <10000 9800 9600 9400 9200 9000>, <8800 8600 8400 8200 8000 7800>, <7600 7400 7200 7000 6800 6600>, <6400 6200 6000 5800 5600 5400>, <5200 5000 4800 4600 4400 4200>, <4000 3800 3600 3400 3200 3000>, <2800 2600 2400 2200 2000 1800>, <1600 1400 1200 1000 900 800>, <700 600 500 400 300 200>, <100 0>;
				qcom,lut-data = <6322 5653 5290 5075 5036 5024>, <6288 5657 5289 5075 5035 5025>, <6255 5658 5288 5075 5034 5026>, <6224 5657 5286 5075 5034 5027>, <6197 5653 5283 5075 5034 5027>, <6175 5648 5280 5075 5034 5028>, <6159 5641 5275 5076 5035 5028>, <6145 5632 5271 5077 5036 5028>, <6124 5624 5267 5078 5037 5028>, <6088 5616 5264 5079 5038 5029>, <6066 5612 5262 5081 5040 5030>, <6078 5616 5262 5083 5041 5031>, <6103 5625 5263 5085 5043 5033>, <6101 5627 5266 5088 5046 5035>, <6034 5620 5276 5093 5049 5036>, <5964 5610 5283 5099 5052 5038>, <5929 5591 5283 5103 5054 5041>, <5904 5564 5282 5106 5057 5043>, <5898 5547 5278 5111 5061 5047>, <5898 5536 5258 5120 5071 5055>, <5899 5528 5236 5126 5076 5060>, <5886 5519 5221 5111 5065 5052>, <5857 5511 5209 5084 5046 5035>, <5848 5504 5203 5072 5037 5027>, <5855 5498 5199 5068 5032 5024>, <5866 5494 5197 5066 5030 5022>, <5880 5495 5197 5066 5030 5022>, <5900 5500 5199 5068 5031 5022>, <5919 5507 5199 5069 5032 5023>, <5936 5526 5198 5072 5035 5025>, <5953 5550 5198 5074 5038 5029>, <5972 5572 5201 5076 5042 5032>, <5992 5594 5209 5079 5045 5036>, <6012 5618 5217 5081 5046 5038>, <6032 5644 5228 5083 5046 5039>, <6052 5673 5241 5084 5046 5039>, <6075 5703 5253 5084 5043 5036>, <6099 5735 5267 5083 5037 5029>, <6124 5768 5280 5083 5036 5027>, <6148 5800 5293 5083 5039 5032>, <6173 5835 5307 5084 5040 5035>, <6198 5874 5322 5086 5040 5034>, <6224 5919 5339 5088 5039 5031>, <6259 5964 5362 5090 5036 5026>, <6306 6018 5392 5095 5037 5027>, <6357 6073 5406 5100 5050 5044>, <6345 6066 5411 5105 5061 5056>, <6394 6118 5443 5117 5072 5067>, <6451 6174 5477 5129 5081 5074>, <6515 6234 5513 5131 5071 5057>, <6569 6280 5529 5113 5050 5041>, <6653 6331 5566 5117 5052 5043>, <6806 6433 5647 5136 5060 5049>, <7217 6566 5754 5167 5083 5075>, <7217 6566 5754 5167 5083 5075>, <7217 6566 5754 5167 5083 5075>;
			};
		};
	};
};

&soc {
	/delete-node/ ssphy@88e8000;

	xiaomi_touch {
		compatible = "xiaomi-touch";
		status = "ok";
		touch,name = "xiaomi-touch";
	};

	/* FROM-4.14 (dt/414/xiaomi/davinci/davinci-sdmmagpie-camera-sensor.dtsi): target only, 4.14 bindings, check */
	led_flash_rear: qcom,camera-flash@0 {
		cell-index = <0>;
		reg = <0x00 0x00>;
		compatible = "qcom,camera-flash";
		flash-source = <&pm6150l_flash0 &pm6150l_flash1>;
		torch-source = <&pm6150l_torch0 &pm6150l_torch1>;
		switch-source = <&pm6150l_switch2 &pm6150l_switch2>;
		status = "ok";
	};

	/* FROM-4.14 (dt/414/xiaomi/davinci/davinci-sdmmagpie-camera-sensor.dtsi): target only, 4.14 bindings, check */
	led_flash_rear_aux: qcom,camera-flash@1 {
		cell-index = <1>;
		reg = <0x01 0x00>;
		compatible = "qcom,camera-flash";
		flash-source = <&pm6150l_flash0 &pm6150l_flash1>;
		torch-source = <&pm6150l_torch0 &pm6150l_torch1>;
		switch-source = <&pm6150l_switch2 &pm6150l_switch2>;
		status = "ok";
	};

	/* FROM-4.14 (dt/414/xiaomi/davinci/davinci-sdmmagpie-camera-sensor.dtsi): target only, 4.14 bindings, check */
	led_flash_rear_aux2: qcom,camera-flash@2 {
		cell-index = <2>;
		reg = <0x02 0x00>;
		compatible = "qcom,camera-flash";
		flash-source = <&pm6150l_flash0 &pm6150l_flash1>;
		torch-source = <&pm6150l_torch0 &pm6150l_torch1>;
		switch-source = <&pm6150l_switch2 &pm6150l_switch2>;
		status = "ok";
	};

	/* FROM-4.14 (dt/414/xiaomi/davinci/davinci-sdmmagpie-camera-sensor.dtsi): target only, 4.14 bindings, check */
	tele_actuator_regulator: gpio-regulator@1 {
		compatible = "regulator-fixed";
		reg = <0x01 0x00>;
		regulator-name = "actuator_regulator";
		regulator-min-microvolt = <2800000>;
		regulator-max-microvolt = <2800000>;
		regulator-enable-ramp-delay = <100>;
		enable-active-high;
		gpio = <&pm6150l_gpios 11 0>;
		pinctrl-names = "default";
		pinctrl-0 = <&cam_actuator_tele_en>;
		vin-supply = <&pm6150l_bob>;
	};

	/* FROM-4.14 (dt/414/xiaomi/davinci/davinci-sdmmagpie.dtsi): target only, 4.14 bindings, check */
	fingerprint_goodix {
		compatible = "goodix,fingerprint";
		goodix,gpio-reset = <&tlmm 65 0x0>;
		goodix,gpio-irq = <&tlmm 69 0x0>;
		fp-gpio-pwr = <&tlmm 63 0>;
		status = "ok";
	};

	/* FROM-4.14 (dt/414/xiaomi/davinci/davinci-sdmmagpie.dtsi): target only, 4.14 bindings, check */
	ti,drv8846@0 {
		cell-index = <0>;
		reg = <0x00 0x00>;
		compatible = "ti,drv8846";
		pwms = <&pm6150l_pwm 1 1000000>;
		motor,gpio-mode0 = <&tlmm 91 0x00>;
		motor,gpio-mode1 = <&tlmm 66 0x00>;
		motor,gpio-sleep = <&tlmm 88 0x00>;
		motor,gpio-dir = <&tlmm 55 0x00>;
		motor,gpio-pwren = <&tlmm 90 0x00>;
		motor,rampup-pwm-period-ns = <625000>;
		motor,rampup-duration-ms = <50>;
		motor,high-pwm-period-ns = <52083>;
		motor,high-duration-ms = <720>;
		motor,rampdown-pwm-period-ns = <625000>;
		motor,rampdown-duration-ms = <50>;
		motor,step-mode = <2>;
		pinctrl-names = "default";
		pinctrl-0 = <&pwm_out_gpio10_default &motor_gpio_default &motor_gpio_fault>;
		status = "ok";
	};
};

&pm6150_vadc {

	pa_therm1 {
		reg = <ADC5_AMUX_THM2_100K_PU>;
		label = "pa_therm1";
		qcom,ratiometric;
		qcom,hw-settle-time = <200>;
		qcom,pre-scaling = <1 1>;
	};

	emmc_ufs_therm {
		reg = <ADC5_AMUX_THM3_100K_PU>;
		label = "emmc_ufs_therm";
		qcom,ratiometric;
		qcom,hw-settle-time = <200>;
		qcom,pre-scaling = <1 1>;
	};

	quiet_therm {
		reg = <ADC5_AMUX_THM4_100K_PU>;
		label = "quiet_therm";
		qcom,ratiometric;
		qcom,hw-settle-time = <200>;
		qcom,pre-scaling = <1 1>;
	};
};

&pm6150_charger {
	/* MERGE io-channels: 4.14 target has <&pm6150_vadc ADC5_USB_IN_V_16>, <&pm6150_vadc ADC5_USB_IN_I>, <&pm6150_vadc ADC5_CHG_TEMP>, <&pm6150_vadc ADC5_DIE_TEMP>, <&pm6150l_vadc ADC5_AMUX_THM1_100K_PU>, <&pm6150_vadc ADC_SBUx>, <&pm6150_vadc ADC5_VPH_PWR> */
	/* MERGE io-channel-names: 4.14 target has "usb_in_voltage",
			   "usb_in_current",
			   "chg_temp",
			   "die_temp",
			   "conn_temp",
			   "sbux_res",
			   "vph_voltage" */
	io-channels = <&pm6150_vadc ADC5_USB_IN_V_16>, <&pm6150_vadc ADC5_USB_IN_I>, <&pm6150_vadc ADC5_CHG_TEMP>, <&pm6150_vadc ADC5_DIE_TEMP>, <&pm6150l_vadc ADC5_AMUX_THM1_100K_PU>, <&pm6150_vadc ADC5_SBUx>, <&pm6150_vadc ADC5_VPH_PWR>, <&pm6150_qg PSY_IIO_RESISTANCE_ID>, <&pm6150_qg PSY_IIO_VOLTAGE_NOW>, <&pm6150_qg PSY_IIO_TEMP>, <&pm6150_qg PSY_IIO_CAPACITY>, <&pm6150_qg PSY_IIO_VOLTAGE_OCV>, <&pm6150_qg PSY_IIO_VOLTAGE_AVG>, <&pm6150_qg PSY_IIO_DEBUG_BATTERY>, <&pm6150_qg PSY_IIO_REAL_CAPACITY>, <&pm6150_qg PSY_IIO_CC_SOC>, <&pm6150_qg PSY_IIO_CURRENT_NOW>, <&pm6150_qg PSY_IIO_VOLTAGE_MAX>, <&pm6150_qg PSY_IIO_CHARGE_FULL>, <&pm6150_qg PSY_IIO_CHARGE_COUNTER>, <&pm6150_qg PSY_IIO_CYCLE_COUNT>, <&pm6150_qg PSY_IIO_CHARGE_FULL_DESIGN>, <&pm6150_qg PSY_IIO_TIME_TO_FULL_NOW>;
	io-channel-names = "usb_in_voltage", "usb_in_current", "chg_temp", "die_temp", "conn_temp", "sbux_res", "vph_voltage", "resistance_id", "voltage_now", "temp", "capacity", "voltage_ocv", "voltage_avg", "debug_battery", "real_capacity", "cc_soc", "current_now", "voltage_max", "charge_full", "charge_counter", "cycle_count", "charge_full_design", "time_to_full_now";
	qcom,battery-data = <&mtp_batterydata>;
	dpdm-supply = <&qusb_phy0>;
	qcom,sec-charger-config = <1>;
	qcom,chg-term-src = <1>;
	qcom,chg-term-current-ma = <(-200)>;
	qcom,auto-recharge-soc = <99>;
	qcom,sw-jeita-enable;
	qcom,thermal-mitigation = <3500000 3400000 3300000 3200000 3100000 3000000 2900000 2800000 2600000 2400000 2200000 2000000 1800000 1500000 1000000 500000>;
	qcom,thermal-mitigation-icl = <2800000 2700000 2600000 2400000 2200000 2100000 2000000 2000000 2000000 1900000 1800000 1600000 1500000 1300000 1000000 750000>;
	qcom,thermal-mitigation-dcp = <1800000 1800000 1800000 1800000 1800000 1800000 1800000 1800000 1800000 1700000 1600000 1400000 1200000 1100000 1100000 1000000>;
	qcom,thermal-mitigation-qc2 = <1500000 1500000 1500000 1500000 1450000 1400000 1350000 1300000 1150000 1100000 1000000 900000 850000 750000 650000 500000>;
	qcom,thermal-fcc-qc3-normal = <3500000 3400000 3300000 3200000 3100000 3000000 2900000 2800000 2700000 2600000 2400000 2200000 2000000 2000000 750000 700000>;
	qcom,thermal-mitigation-pd-base = <3500000 3500000 3500000 3500000 3400000 3300000 3200000 3100000 3000000 2800000 2600000 2400000 2200000 2000000 1000000 700000>;
	qcom,usb-icl-ua = <2800000>;
	qcom,fcc-max-ua = <3500000>;
	qcom,fv-max-uv = <4400000>;
	qcom,dynamic-fv-enable;
	qcom,lpd-disable;
	mi,early-status-report;
	qcom,thermal-fcc-qc3-cp = <3500000 3500000 3500000 3500000 3400000 3300000 3200000 3100000 3000000 2800000 2600000 2400000 2200000 2000000 1000000 700000>;
	qcom,thermal-fcc-pps-cp = <3500000 3500000 3500000 3500000 3400000 3300000 3200000 3100000 3000000 2800000 2600000 2400000 2200000 2000000 1000000 700000>;
};

&pm6150_qg {
	qcom,battery-data = <&mtp_batterydata>;
	qcom,qg-iterm-ma = <350>;
	qcom,s3-entry-ibat-ua = <25000>;
	qcom,s3-exit-ibat-ua = <45000>;
	qcom,hold-soc-while-full;
	qcom,linearize-soc;
	qcom,cl-feedback-on;
	qcom,shutdown-soc-threshold = <3>;
	qcom,shutdown-delay-enable;
};

&pm6150_adc_tm {
	/* board ADC-TM channels: 4.14 board file in the 6.1 ADC-TM5 form */
	status = "okay";

	xo-therm@0 {
		reg = <0>;
		io-channels = <&pm6150_vadc ADC5_XO_THERM_100K_PU>;
		qcom,ratiometric;
		qcom,hw-settle-time-us = <200>;
	};

	pa-therm1@1 {
		reg = <1>;
		io-channels = <&pm6150_vadc ADC5_AMUX_THM2_100K_PU>;
		qcom,ratiometric;
		qcom,hw-settle-time-us = <200>;
	};

	emmc-ufs-therm@2 {
		reg = <2>;
		io-channels = <&pm6150_vadc ADC5_AMUX_THM3_100K_PU>;
		qcom,ratiometric;
		qcom,hw-settle-time-us = <200>;
	};

	quiet-therm@3 {
		reg = <3>;
		io-channels = <&pm6150_vadc ADC5_AMUX_THM4_100K_PU>;
		qcom,ratiometric;
		qcom,hw-settle-time-us = <200>;
	};
};

&pm6150l_lcdb {
	status = "disabled";
};

&pm6150l_lpg {
	qcom,lut-patterns = <0 1 2 3 4 5 6 7 8 9 10 11 12 13 12 11 10 9 8 7 6 5 4 3 2 1 0>;
	qcom,lut-pattern-switch;
	qcom,lut-patterns-camera = <0 1 3 5 8 10 12 15 18 22 26 32 38 44 50 60 72 82 90 96 98 99 100 99 98 96 90 82 72 60 50 44 38 32 26 22 18 15 12 10 8 5 3 1 0>;
};

&pm6150l_wled {
	status = "disabled";
};

&pm6150l_pwm {
	status = "okay";
};

&pm6150l_vadc {

	conn_therm {
		reg = <ADC5_AMUX_THM1_100K_PU>;
		label = "conn_therm";
		qcom,ratiometric;
		qcom,hw-settle-time = <200>;
		qcom,pre-scaling = <1 1>;
	};

	smb_therm {
		reg = <ADC5_AMUX_THM2>;
		label = "smb_therm";
		qcom,hw-settle-time = <200>;
		qcom,pre-scaling = <1 1>;
	};

	camera_ftherm {
		reg = <ADC5_AMUX_THM3_100K_PU>;
		label = "camera_ftherm";
		qcom,ratiometric;
		qcom,hw-settle-time = <200>;
		qcom,pre-scaling = <1 1>;
	};

	nvm_therm {
		reg = <ADC5_GPIO4_100K_PU>;
		label = "nvm_therm";
		qcom,ratiometric;
		qcom,hw-settle-time = <200>;
		qcom,pre-scaling = <1 1>;
	};
};

&pm6150l_adc_tm {
	/* board ADC-TM channels: 4.14 board file in the 6.1 ADC-TM5 form */
	status = "okay";

	conn-therm@0 {
		reg = <0>;
		io-channels = <&pm6150l_vadc ADC5_AMUX_THM1_100K_PU>;
		qcom,ratiometric;
		qcom,hw-settle-time-us = <200>;
	};

	camera-ftherm@1 {
		reg = <1>;
		io-channels = <&pm6150l_vadc ADC5_AMUX_THM3_100K_PU>;
		qcom,ratiometric;
		qcom,hw-settle-time-us = <200>;
	};

	nvm-therm@2 {
		reg = <2>;
		io-channels = <&pm6150l_vadc ADC5_GPIO4_100K_PU>;
		qcom,ratiometric;
		qcom,hw-settle-time-us = <200>;
	};
};

&pm6150l_gpios {

	/* FROM-4.14 (dt/414/xiaomi/davinci/davinci-sdmmagpie-pinctrl.dtsi): target only, 4.14 bindings, check */
	cam_actuator_wide_en: cam_actuator_wide_en {
		pins = "gpio12";
		function = "normal";
		power-source = <1>;
		output-low;
	};

	/* FROM-4.14 (dt/414/xiaomi/davinci/davinci-sdmmagpie-pinctrl.dtsi): target only, 4.14 bindings, check */
	cam_actuator_tele_en: cam_actuator_tele_en {
		pins = "gpio11";
		function = "normal";
		power-source = <1>;
		output-low;
	};

	/* FROM-4.14 (dt/414/xiaomi/davinci/davinci-sdmmagpie-pinctrl.dtsi): target only, 4.14 bindings, check */
	cam_sensor_w_ldo_en_active: cam_sensor_w_ldo_en_active {
		pins = "gpio3";
		function = "normal";
		power-source = <0>;
		output-low;
	};

	/* FROM-4.14 (dt/414/xiaomi/davinci/davinci-sdmmagpie-pinctrl.dtsi): target only, 4.14 bindings, check */
	cam_sensor_w_ldo_en_suspend: cam_sensor_w_ldo_en_suspend {
		pins = "gpio3";
		function = "normal";
		power-source = <0>;
		output-low;
	};

	/* FROM-4.14 (dt/414/xiaomi/davinci/davinci-sdmmagpie-pinctrl.dtsi): target only, 4.14 bindings, check */
	cam_sensor_t_ldo_en_active: cam_sensor_t_ldo_en_active {
		pins = "gpio8";
		function = "normal";
		power-source = <0>;
		output-low;
	};

	/* FROM-4.14 (dt/414/xiaomi/davinci/davinci-sdmmagpie-pinctrl.dtsi): target only, 4.14 bindings, check */
	cam_sensor_t_ldo_en_suspend: cam_sensor_t_ldo_en_suspend {
		pins = "gpio8";
		function = "normal";
		power-source = <0>;
		output-low;
	};

	/* FROM-4.14 (dt/414/xiaomi/davinci/davinci-sdmmagpie-pinctrl.dtsi): target only, 4.14 bindings, check */
	pwm_out_gpio10 {

		/* FROM-4.14 (dt/414/xiaomi/davinci/davinci-sdmmagpie-pinctrl.dtsi): target only, 4.14 bindings, check */
		pwm_out_gpio10_default: pwm_out_gpio10_default {
			pins = "gpio10";
			function = "func1";
			bias-disable;
			power-source = <1>;
			output-low;
			qcom,drive-strength = <3>;
			drive-push-pull;
		};
	};

	/* FROM-4.14 (dt/414/xiaomi/davinci/davinci-sdmmagpie.dtsi): target only, 4.14 bindings, check */
	nvm_therm {

		/* FROM-4.14 (dt/414/xiaomi/davinci/davinci-sdmmagpie.dtsi): target only, 4.14 bindings, check */
		nvm_therm_default: nvm_therm_default {
			pins = "gpio10";
			bias-high-impedance;
		};
	};
};

&thermal_zones {

	/* board thermistor zone, 4.14 name and trips */
	xo_therm {
		polling-delay-passive = <0>;
		polling-delay = <0>;
		thermal-sensors = <&pm6150_adc_tm 0>;

		trips {

			active-config0 {
				temperature = <125000>;
				hysteresis = <1000>;
				type = "passive";
			};
		};
	};

	/* board thermistor zone, 4.14 name and trips */
	pa_therm1 {
		polling-delay-passive = <0>;
		polling-delay = <0>;
		thermal-sensors = <&pm6150_adc_tm 1>;

		trips {

			active-config0 {
				temperature = <125000>;
				hysteresis = <1000>;
				type = "passive";
			};
		};
	};

	/* board thermistor zone, 4.14 name and trips */
	emmc_ufs_therm {
		polling-delay-passive = <0>;
		polling-delay = <0>;
		thermal-sensors = <&pm6150_adc_tm 2>;

		trips {

			active-config0 {
				temperature = <125000>;
				hysteresis = <1000>;
				type = "passive";
			};
		};
	};

	/* board thermistor zone, 4.14 name and trips */
	quiet_therm {
		polling-delay-passive = <0>;
		polling-delay = <0>;
		thermal-sensors = <&pm6150_adc_tm 3>;

		trips {

			active-config0 {
				temperature = <125000>;
				hysteresis = <1000>;
				type = "passive";
			};
		};
	};

	/* board thermistor zone, 4.14 name and trips */
	conn_therm {
		polling-delay-passive = <0>;
		polling-delay = <0>;
		thermal-sensors = <&pm6150l_adc_tm 0>;

		trips {

			active-config0 {
				temperature = <125000>;
				hysteresis = <1000>;
				type = "passive";
			};
		};
	};
};

&qcom_smcinvoke {
	reg = <0x86d00000 0x3E00000>;
};

&tlmm {

	pmx_ts_active {

		tp_active: tp_active {

			mux {
				pins = "gpio9", "gpio8";
				function = "gpio";
			};

			config {
				pins = "gpio9", "gpio8";
				drive-strength = <16>;
				bias-pull-up;
			};
		};
	};

	pmx_ts_int_suspend {

		tp_int_suspend: tp_int_suspend {

			mux {
				pins = "gpio9";
				function = "gpio";
			};

			config {
				pins = "gpio9";
				drive-strength = <16>;
				input-enable;
				slew-rate = <0>;
				bias-pull-up = <00>;
			};
		};
	};

	pmx_ts_reset_suspend {

		tp_reset_suspend: tp_reset_suspend {

			mux {
				pins = "gpio8";
				function = "gpio";
			};

			config {
				pins = "gpio8";
				drive-strength = <16>;
				slew-rate = <1>;
				bias-disable;
				output-high;
			};
		};
	};

	cam_sensor_active_wide: cam_sensor_active_wide {

		mux {
			pins = "gpio26";
			function = "gpio";
		};

		config {
			pins = "gpio26";
			bias-disable;
			drive-strength = <2>;
		};
	};

	cam_sensor_suspend_wide: cam_sensor_suspend_wide {

		mux {
			pins = "gpio26";
			function = "gpio";
		};

		config {
			pins = "gpio26";
			bias-pull-down;
			drive-strength = <2>;
			output-low;
		};
	};

	cam_sensor_active_tele: cam_sensor_active_tele {

		mux {
			pins = "gpio24";
			function = "gpio";
		};

		config {
			pins = "gpio24";
			bias-disable;
			drive-strength = <2>;
		};
	};

	cam_sensor_suspend_tele: cam_sensor_suspend_tele {

		mux {
			pins = "gpio24";
			function = "gpio";
		};

		config {
			pins = "gpio24";
			bias-pull-down;
			drive-strength = <2>;
			output-low;
		};
	};

	cam_sensor_active_ultra: cam_sensor_active_ultra {

		mux {
			pins = "gpio25", "gpio29";
			function = "gpio";
		};

		config {
			pins = "gpio25", "gpio29";
			bias-disable;
			drive-strength = <2>;
		};
	};

	cam_sensor_suspend_ultra: cam_sensor_suspend_ultra {

		mux {
			pins = "gpio25", "gpio29";
			function = "gpio";
		};

		config {
			pins = "gpio25", "gpio29";
			bias-pull-down;
			drive-strength = <2>;
			output-low;
		};
	};

	cam_sensor_active_front: cam_sensor_active_front {

		mux {
			pins = "gpio23", "gpio57";
			function = "gpio";
		};

		config {
			pins = "gpio23", "gpio57";
			bias-disable;
			drive-strength = <2>;
		};
	};

	cam_sensor_suspend_front: cam_sensor_suspend_front {

		mux {
			pins = "gpio23", "gpio57";
			function = "gpio";
		};

		config {
			pins = "gpio23", "gpio57";
			bias-pull-down;
			drive-strength = <2>;
			output-low;
		};
	};

	motor_gpio_default: motor_gpio_default {

		mux {
			pins = "gpio55", "gpio91", "gpio66", "gpio88", "gpio90";
			function = "gpio";
		};

		config {
			pins = "gpio55", "gpio91", "gpio66", "gpio88", "gpio90";
			bias-pull-up;
			drive-strength = <2>;
		};
	};

	motor_gpio_fault: motor_gpio_fault {

		mux {
			pins = "gpio43";
			function = "gpio";
		};

		config {
			pins = "gpio43";
			bias-pull-up;
			drive-strength = <2>;
		};
	};

	akm09970_irq {

		akm_irq_active: akm_irq_active {

			mux {
				pins = "gpio93";
				function = "gpio";
			};

			config {
				pins = "gpio93";
				drive-strength = <2>;
				bias-pull-up;
			};
		};

		akm_irq_suspend: akm_irq_suspend {

			mux {
				pins = "gpio93";
				function = "gpio";
			};

			config {
				pins = "gpio93";
				drive-strength = <2>;
				bias-disable;
			};
		};
	};

	akm09970_reset {

		akm_reset_active: akm_reset_active {

			mux {
				pins = "gpio64";
				function = "gpio";
			};

			config {
				pins = "gpio64";
				drive-strength = <2>;
				bias-pull-down;
				output-low;
			};
		};

		akm_reset_suspend: akm_reset_suspend {

			mux {
				pins = "gpio64";
				function = "gpio";
			};

			config {
				pins = "gpio64";
				drive-strength = <2>;
				bias-disable;
			};
		};
	};

	msm_gpio_65: msm_gpio_65 {

		mux {
			pins = "gpio65";
			function = "gpio";
		};

		config {
			pins = "gpio65";
			drive-strength = <2>;
			bias-disable;
			output-low;
		};
	};

	msm_gpio_65_output_high: msm_gpio_65_output_high {

		mux {
			pins = "gpio65";
			function = "gpio";
		};

		config {
			pins = "gpio65";
			drive-strength = <2>;
			bias-disable;
			output-high;
		};
	};

	msm_gpio_69: msm_gpio_69 {

		mux {
			pins = "gpio69";
			function = "gpio";
		};

		config {
			pins = "gpio69";
			drive-strength = <2>;
			bias-pull-down;
		};
	};
};

&usb0 {

	dwc3@a600000 {
		usb-phy = <&qusb_phy0>, <&usb_nop_phy>;
		maximum-speed = "high-speed";
	};
};

&cam_cci {

	/* FROM-4.14 (dt/414/xiaomi/davinci/davinci-sdmmagpie-camera-sensor.dtsi): target only, 4.14 bindings, check */
	qcom,cam-res-mgr {
		compatible = "qcom,cam-res-mgr";
		status = "ok";
	};

	/* FROM-4.14 (dt/414/xiaomi/davinci/davinci-sdmmagpie-camera-sensor.dtsi): target only, 4.14 bindings, check */
	actuator_rear: qcom,actuator@0 {
		cell-index = <0>;
		reg = <0x0>;
		compatible = "qcom,actuator";
		cci-master = <0>;
		cam_vaf-supply = <&wide_actuator_regulator>;
		regulator-names = "cam_vaf";
		rgltr-cntrl-support;
		rgltr-min-voltage = <2800000>;
		rgltr-max-voltage = <2800000>;
		rgltr-load-current = <220000>;
	};

	/* FROM-4.14 (dt/414/xiaomi/davinci/davinci-sdmmagpie-camera-sensor.dtsi): target only, 4.14 bindings, check */
	actuator_rear_aux: qcom,actuator@1 {
		cell-index = <1>;
		reg = <0x1>;
		compatible = "qcom,actuator";
		cci-master = <1>;
		cam_vaf-supply = <&tele_actuator_regulator>;
		regulator-names = "cam_vaf";
		rgltr-cntrl-support;
		rgltr-min-voltage = <2800000>;
		rgltr-max-voltage = <2800000>;
		rgltr-load-current = <220000>;
	};

	/* FROM-4.14 (dt/414/xiaomi/davinci/davinci-sdmmagpie-camera-sensor.dtsi): target only, 4.14 bindings, check */
	eeprom_rear: qcom,eeprom@0 {
		cell-index = <0>;
		reg = <0>;
		compatible = "qcom,eeprom";
		cam_vio-supply = <&pm6150_l16>;
		cam_vaf-supply = <&wide_actuator_regulator>;
		cam_clk-supply = <&titan_top_gdsc>;
		regulator-names = "cam_vio", "cam_vaf", "cam_clk";
		rgltr-cntrl-support;
		rgltr-min-voltage = <1800000 2800000 0>;
		rgltr-max-voltage = <1800000 2800000 0>;
		rgltr-load-current = <60000 220000 0>;
		gpio-no-mux = <0>;
		pinctrl-names = "cam_default", "cam_suspend";
		pinctrl-0 = <&cam_sensor_mclk2_active &cam_sensor_active_wide>;
		pinctrl-1 = <&cam_sensor_mclk2_suspend &cam_sensor_suspend_wide>;
		gpios = <&tlmm 15 0>;
		gpio-req-tbl-num = <0>;
		gpio-req-tbl-flags = <1>;
		gpio-req-tbl-label = "CAMIF_MCLK2";
		sensor-mode = <0>;
		cci-master = <0>;
		cci-device = <0>;
		status = "ok";
		clocks = <&camcc CAM_CC_MCLK2_CLK>;
		clock-names = "cam_clk";
		clock-cntl-level = "turbo";
		clock-rates = <19200000>;
	};

	/* FROM-4.14 (dt/414/xiaomi/davinci/davinci-sdmmagpie-camera-sensor.dtsi): target only, 4.14 bindings, check */
	eeprom_rear_aux: qcom,eeprom@1 {
		cell-index = <1>;
		reg = <0x1>;
		compatible = "qcom,eeprom";
		cam_vio-supply = <&pm6150_l16>;
		cam_vaf-supply = <&tele_actuator_regulator>;
		cam_clk-supply = <&titan_top_gdsc>;
		regulator-names = "cam_vio", "cam_vaf", "cam_clk";
		rgltr-cntrl-support;
		rgltr-min-voltage = <1800000 2800000 0>;
		rgltr-max-voltage = <1800000 2800000 0>;
		rgltr-load-current = <60000 220000 0>;
		gpio-no-mux = <0>;
		pinctrl-names = "cam_default", "cam_suspend";
		pinctrl-0 = <&cam_sensor_mclk3_active &cam_sensor_active_tele>;
		pinctrl-1 = <&cam_sensor_mclk3_suspend &cam_sensor_suspend_tele>;
		gpios = <&tlmm 16 0>;
		gpio-req-tbl-num = <0>;
		gpio-req-tbl-flags = <1>;
		gpio-req-tbl-label = "CAMIF_MCLK3";
		sensor-mode = <0>;
		cci-master = <1>;
		cci-device = <0>;
		status = "ok";
		clocks = <&camcc CAM_CC_MCLK3_CLK>;
		clock-names = "cam_clk";
		clock-cntl-level = "turbo";
		clock-rates = <19200000>;
	};

	/* FROM-4.14 (dt/414/xiaomi/davinci/davinci-sdmmagpie-camera-sensor.dtsi): target only, 4.14 bindings, check */
	eeprom_front: qcom,eeprom@2 {
		cell-index = <2>;
		reg = <0x2>;
		compatible = "qcom,eeprom";
		cam_vio-supply = <&pm6150_l16>;
		cam_clk-supply = <&titan_top_gdsc>;
		regulator-names = "cam_vio", "cam_clk";
		rgltr-cntrl-support;
		rgltr-min-voltage = <1800000 0>;
		rgltr-max-voltage = <1800000 0>;
		rgltr-load-current = <60000 0>;
		gpio-no-mux = <0>;
		pinctrl-names = "cam_default", "cam_suspend";
		pinctrl-0 = <&cam_sensor_mclk0_active &cam_sensor_active_front>;
		pinctrl-1 = <&cam_sensor_mclk0_suspend &cam_sensor_suspend_front>;
		gpios = <&tlmm 13 0>;
		gpio-req-tbl-num = <0>;
		gpio-req-tbl-flags = <1>;
		gpio-req-tbl-label = "CAMIF_MCLK0";
		sensor-mode = <0>;
		cci-device = <0>;
		cci-master = <0>;
		status = "ok";
		clocks = <&camcc CAM_CC_MCLK0_CLK>;
		clock-names = "cam_clk";
		clock-cntl-level = "turbo";
		clock-rates = <19200000>;
	};

	/* FROM-4.14 (dt/414/xiaomi/davinci/davinci-sdmmagpie-camera-sensor.dtsi): target only, 4.14 bindings, check */
	qcom,cam-sensor@0 {
		cell-index = <0>;
		compatible = "qcom,cam-sensor";
		reg = <0x0>;
		csiphy-sd-index = <0>;
		sensor-position-roll = <90>;
		sensor-position-pitch = <0>;
		sensor-position-yaw = <180>;
		led-flash-src = <&led_flash_rear>;
		actuator-src = <&actuator_rear>;
		eeprom-src = <&eeprom_rear>;
		cam_vio-supply = <&pm6150_l16>;
		cam_vana-supply = <&pm6150l_bob>;
		cam_vdig-supply = <&pm6150l_s8>;
		cam_clk-supply = <&titan_top_gdsc>;
		cam_v_custom2-supply = <&pm6150l_l9>;
		regulator-names = "cam_vio", "cam_vana", "cam_vdig",
			"cam_clk", "cam_v_custom2";
		rgltr-cntrl-support;
		rgltr-min-voltage = <1800000 3008000 1352000 0 2856000>;
		rgltr-max-voltage = <1800000 4000000 1352000 0 3008000>;
		rgltr-load-current = <60000 120000 1200000 0 100000>;
		gpio-no-mux = <0>;
		pinctrl-names = "cam_default", "cam_suspend";
		pinctrl-0 = <&cam_sensor_mclk2_active &cam_sensor_active_wide &cam_sensor_w_ldo_en_active>;
		pinctrl-1 = <&cam_sensor_mclk2_suspend &cam_sensor_suspend_wide &cam_sensor_w_ldo_en_suspend>;
		gpios = <&tlmm 15 0>, <&tlmm 26 0>, <&pm6150l_gpios 3 0>;
		gpio-reset = <1>;
		gpio-vdig = <2>;
		gpio-req-tbl-num = <0 1 2>;
		gpio-req-tbl-flags = <1 0 0>;
		gpio-req-tbl-label = "CAMIF_MCLK2",
					"CAMW_RESET",
					"CAMW_VDIG_EN";
		sensor-mode = <0>;
		cci-master = <0>;
		cci-device = <0>;
		status = "ok";
		clocks = <&camcc CAM_CC_MCLK2_CLK>;
		clock-names = "cam_clk";
		clock-cntl-level = "turbo";
		clock-rates = <19200000>;
	};

	/* FROM-4.14 (dt/414/xiaomi/davinci/davinci-sdmmagpie-camera-sensor.dtsi): target only, 4.14 bindings, check */
	qcom,cam-sensor@1 {
		cell-index = <1>;
		compatible = "qcom,cam-sensor";
		reg = <0x1>;
		csiphy-sd-index = <3>;
		sensor-position-roll = <90>;
		sensor-position-pitch = <0>;
		sensor-position-yaw = <180>;
		actuator-src = <&actuator_rear_aux>;
		led-flash-src = <&led_flash_rear_aux>;
		eeprom-src = <&eeprom_rear_aux>;
		cam_vio-supply = <&pm6150_l16>;
		cam_vana-supply = <&pm6150l_bob>;
		cam_vdig-supply = <&pm6150l_s8>;
		cam_clk-supply = <&titan_top_gdsc>;
		cam_v_custom1-supply = <&pm6150l_l9>;
		regulator-names = "cam_vio", "cam_vana", "cam_vdig",
			"cam_clk", "cam_v_custom1";
		rgltr-cntrl-support;
		rgltr-min-voltage = <1800000 3008000 1352000 0 2856000>;
		rgltr-max-voltage = <1800000 4000000 1352000 0 3008000>;
		rgltr-load-current = <60000 120000 1200000 0 100000>;
		gpio-no-mux = <0>;
		pinctrl-names = "cam_default", "cam_suspend";
		pinctrl-0 = <&cam_sensor_mclk3_active &cam_sensor_active_tele &cam_sensor_t_ldo_en_active>;
		pinctrl-1 = <&cam_sensor_mclk3_suspend &cam_sensor_suspend_tele &cam_sensor_t_ldo_en_suspend>;
		gpios = <&tlmm 16 0>, <&tlmm 24 0>, <&pm6150l_gpios 8 0>;
		gpio-reset = <1>;
		gpio-vdig = <2>;
		gpio-req-tbl-num = <0 1 2>;
		gpio-req-tbl-flags = <1 0 0>;
		gpio-req-tbl-label = "CAMIF_MCLK3",
					"CAMT_RESET",
					"CAMT_VDIG_EN";
		sensor-mode = <0>;
		cci-master = <1>;
		cci-device = <0>;
		status = "ok";
		clocks = <&camcc CAM_CC_MCLK3_CLK>;
		clock-names = "cam_clk";
		clock-cntl-level = "turbo";
		clock-rates = <19200000>;
	};

	/* FROM-4.14 (dt/414/xiaomi/davinci/davinci-sdmmagpie-camera-sensor.dtsi): target only, 4.14 bindings, check */
	qcom,cam-sensor@2 {
		cell-index = <2>;
		compatible = "qcom,cam-sensor";
		reg = <0x02>;
		csiphy-sd-index = <1>;
		sensor-position-roll = <270>;
		sensor-position-pitch = <0>;
		sensor-position-yaw = <0>;
		eeprom-src = <&eeprom_front>;
		cam_vio-supply = <&pm6150_l16>;
		cam_vana-supply = <&pm6150l_bob>;
		cam_vdig-supply = <&pm6150l_s8>;
		cam_clk-supply = <&titan_top_gdsc>;
		cam_v_custom1-supply = <&pm6150l_l9>;
		regulator-names = "cam_vio", "cam_vana", "cam_vdig",
			"cam_clk", "cam_v_custom1";
		rgltr-cntrl-support;
		rgltr-min-voltage = <1800000 3008000 1352000 0 2856000>;
		rgltr-max-voltage = <1800000 4000000 1352000 0 3008000>;
		rgltr-load-current = <60000 120000 1200000 0 100000>;
		gpio-no-mux = <0>;
		pinctrl-names = "cam_default", "cam_suspend";
		pinctrl-0 = <&cam_sensor_mclk0_active &cam_sensor_active_front>;
		pinctrl-1 = <&cam_sensor_mclk0_suspend &cam_sensor_suspend_front>;
		gpios = <&tlmm 13 0>, <&tlmm 23 0>, <&tlmm 57 0>;
		gpio-reset = <1>;
		gpio-vdig = <2>;
		gpio-req-tbl-num = <0 1 2>;
		gpio-req-tbl-flags = <1 0 0>;
		gpio-req-tbl-label = "CAMIF_MCLK0",
					"CAMF_RESET",
					"CAMF_VDIG_EN";
		sensor-mode = <0>;
		cci-device = <0>;
		cci-master = <0>;
		status = "ok";
		clocks = <&camcc CAM_CC_MCLK0_CLK>;
		clock-names = "cam_clk";
		clock-cntl-level = "turbo";
		clock-rates = <19200000>;
	};
};

&cam_cci1 {
	gpio-req-tbl-label = "CCI_I2C_DATA2",
				"CCI_I2C_CLK2";

	/* FROM-4.14 (dt/414/xiaomi/davinci/davinci-sdmmagpie-camera-sensor.dtsi): target only, 4.14 bindings, check */
	qcom,cam-res-mgr {
		compatible = "qcom,cam-res-mgr";
		status = "ok";
	};

	/* FROM-4.14 (dt/414/xiaomi/davinci/davinci-sdmmagpie-camera-sensor.dtsi): target only, 4.14 bindings, check */
	eeprom_ultra: qcom,eeprom@3 {
		cell-index = <3>;
		reg = <0x3>;
		compatible = "qcom,eeprom";
		cam_vio-supply = <&pm6150_l16>;
		cam_clk-supply = <&titan_top_gdsc>;
		regulator-names = "cam_vio", "cam_clk";
		rgltr-cntrl-support;
		rgltr-min-voltage = <1800000 0>;
		rgltr-max-voltage = <1800000 0>;
		rgltr-load-current = <60000 0>;
		gpio-no-mux = <0>;
		pinctrl-names = "cam_default", "cam_suspend";
		pinctrl-0 = <&cam_sensor_mclk1_active &cam_sensor_active_ultra>;
		pinctrl-1 = <&cam_sensor_mclk1_suspend &cam_sensor_suspend_ultra>;
		gpios = <&tlmm 14 0>;
		gpio-req-tbl-num = <0>;
		gpio-req-tbl-flags = <1>;
		gpio-req-tbl-label = "CAMIF_MCLK1";
		sensor-mode = <0>;
		cci-master = <0>;
		cci-device = <1>;
		status = "ok";
		clocks = <&camcc CAM_CC_MCLK1_CLK>;
		clock-names = "cam_clk";
		clock-cntl-level = "turbo";
		clock-rates = <19200000>;
	};

	/* FROM-4.14 (dt/414/xiaomi/davinci/davinci-sdmmagpie-camera-sensor.dtsi): target only, 4.14 bindings, check */
	qcom,cam-sensor@3 {
		cell-index = <3>;
		compatible = "qcom,cam-sensor";
		reg = <0x03>;
		csiphy-sd-index = <2>;
		sensor-position-roll = <90>;
		sensor-position-pitch = <0>;
		sensor-position-yaw = <180>;
		led-flash-src = <&led_flash_rear_aux2>;
		eeprom-src = <&eeprom_ultra>;
		cam_vio-supply = <&pm6150_l16>;
		cam_vana-supply = <&pm6150l_bob>;
		cam_vdig-supply = <&pm6150l_s8>;
		cam_clk-supply = <&titan_top_gdsc>;
		cam_v_custom1-supply = <&pm6150l_l9>;
		regulator-names = "cam_vio", "cam_vana", "cam_vdig",
			"cam_clk", "cam_v_custom1";
		rgltr-cntrl-support;
		rgltr-min-voltage = <1800000 3008000 1352000 0 2856000>;
		rgltr-max-voltage = <1800000 4000000 1352000 0 3008000>;
		rgltr-load-current = <60000 120000 1200000 0 100000>;
		gpio-no-mux = <0>;
		pinctrl-names = "cam_default", "cam_suspend";
		pinctrl-0 = <&cam_sensor_mclk1_active &cam_sensor_active_ultra>;
		pinctrl-1 = <&cam_sensor_mclk1_suspend &cam_sensor_suspend_ultra>;
		gpios = <&tlmm 14 0>, <&tlmm 25 0>, <&tlmm 29 0>;
		gpio-reset = <1>;
		gpio-vdig = <2>;
		gpio-req-tbl-num = <0 1 2>;
		gpio-req-tbl-flags = <1 0 0>;
		gpio-req-tbl-label = "CAMIF_MCLK1",
					"CAMU_RESET",
					"CAMU_VDIG_EN";
		sensor-mode = <0>;
		cci-master = <0>;
		cci-device = <1>;
		status = "ok";
		clocks = <&camcc CAM_CC_MCLK1_CLK>;
		clock-names = "cam_clk";
		clock-cntl-level = "turbo";
		clock-rates = <19200000>;
	};
};

&qupv3_se2_i2c {
	status = "ok";
	qcom,clk-freq-out = <1000000>;

	nq@28 {
		compatible = "qcom,nq-nci";
		reg = <0x28>;
		qcom,nq-irq = <&tlmm 37 0x00>;
		qcom,nq-ven = <&tlmm 12 0x00>;
		qcom,nq-firm = <&tlmm 36 0x00>;
		qcom,nq-clkreq = <&tlmm 31 0x00>;
		interrupt-parent = <&tlmm>;
		interrupts = <37 0>;
		interrupt-names = "nfc_irq";
		pinctrl-names = "nfc_active", "nfc_suspend";
		pinctrl-0 = <&nfc_int_active &nfc_enable_active &nfc_clk_req_active>;
		pinctrl-1 = <&nfc_int_suspend &nfc_enable_suspend &nfc_clk_req_suspend>;
	};
};

&qupv3_se4_i2c {
	status = "ok";

	tfa98xx@34 {
		compatible = "nxp,tfa98xx";
		reset-gpio = <&tlmm 67 0>;
		irq-gpio = <&tlmm 56 0>;
		interrupt-parent = <&tlmm>;
		interrupts = <56 0>;
		interrupt-names = "smartpa_irq";
		pinctrl-names = "default", "sleep";
		pinctrl-0 = <&smartpa_int_active &smartpa_enable_active>;
		pinctrl-1 = <&smartpa_int_suspend &smartpa_enable_suspend>;
		reg = <0x34>;
		status = "ok";
	};
};

&qupv3_se8_2uart {
	status = "ok";
};

&qupv3_se7_i2c {
	status = "ok";

	goodix@5d {
		compatible = "goodix,gt9889";
		reg = <0x5d>;
		status = "ok";
		interrupt-parent = <&tlmm>;
		interrupts = <9 0x2800>;
		vtouch-supply = <&pm6150l_l6>;
		vtouch-load = <600000>;
		pinctrl-names = "pmx_ts_active","pmx_ts_suspend";
		pinctrl-0 = <&tp_active>;
		pinctrl-1 = <&tp_int_suspend &tp_reset_suspend>;
		goodix,reset-gpio = <&tlmm 8 0x0>;
		goodix,irq-gpio = <&tlmm 9 0x2800>;
		goodix,avdd-gpio = <&tlmm 5 0x0>;
		goodix,irq-flags = <2>;
		goodix,panel-max-id = <10>;
		goodix,panel-max-x = <1079>;
		goodix,panel-max-y = <2339>;
		goodix,panel-max-w = <127>;
		goodix,panel-max-p = <127>;
		goodix,panel-max-fod = <127>;
		goodix,power-on-delay-us = <300000>;
		goodix,power-off-delay-us = <5000>;
		goodix,cfg-name = "goodix_gt9886_cfg_f10.bin";
		normal-cfg = [ ];

		sensor0 {
			goodix,limit-name = "goodix_gt9886_limit_f10_second.tporder";
			goodix,fw-name = "goodix_gt9886_fw_f10.bin";
			goodix,x2x;
			goodix,y2y;
		};

		sensor1 {
			goodix,limit-name = "goodix_gt9886_limit_f10_first.tporder";
			goodix,fw-name = "goodix_gt9886_fw_f10.bin";
		};
	};
};

&qupv3_se9_i2c {
	status = "ok";

	akm09970@c {
		compatible = "akm,akm09970";
		reg = <0xC>;
		interrupt-parent = <&tlmm>;
		interrupts = <120 0>;
		akm,gpio-reset = <&tlmm 64 0x00>;
		akm,gpio-irq = <&tlmm 93 0x00>;
		akm,measure-freq-hz = <100>;
		vdd-supply = <&pm6150l_l8>;
		pinctrl-names = "akm09970_gpio_active", "akm09970_gpio_suspend";
		pinctrl-0 = <&akm_irq_active &akm_reset_active>;
		pinctrl-1 = <&akm_irq_suspend &akm_reset_suspend>;
		status = "ok";
	};

	/* pinctrl (pm6150 GPIO 3 smb_stat_default) dropped: no pm6150 GPIO node on 6.1 yet */
	smb1390: qcom,smb1390@10 {
		compatible = "qcom,i2c-pmic";
		reg = <0x10>;
		#address-cells = <1>;
		#size-cells = <0>;
		interrupt-parent = <&spmi_bus>;
		interrupt_names = "smb1390";
		interrupt-controller;
		#interrupt-cells = <3>;
		qcom,periph-map = <0x10>;
		status = "ok";
		interrupts = <0x0 0xc2 0x0 IRQ_TYPE_LEVEL_LOW>;

		smb1390_revid: qcom,revid {
			compatible = "qcom,qpnp-revid";
			reg = <0x100>;
		};

		smb1390_charger: qcom,charge_pump {
			compatible = "qcom,smb1390-charger-psy";
			qcom,pmic-revid = <&smb1390_revid>;
			interrupt-parent = <&smb1390>;
			status = "ok";
			io-channels = <&pm6150l_vadc ADC5_AMUX_THM2>;
			io-channel-names = "cp_die_temp";

			qcom,core {
				interrupts = <0x10 0x0 IRQ_TYPE_EDGE_BOTH>, <0x10 0x1 IRQ_TYPE_EDGE_BOTH>, <0x10 0x2 IRQ_TYPE_EDGE_BOTH>, <0x10 0x3 IRQ_TYPE_EDGE_BOTH>, <0x10 0x4 IRQ_TYPE_EDGE_BOTH>, <0x10 0x5 IRQ_TYPE_EDGE_RISING>, <0x10 0x6 IRQ_TYPE_EDGE_RISING>, <0x10 0x7 IRQ_TYPE_EDGE_RISING>;
				interrupt-names = "switcher-off-window",
					  "switcher-off-fault",
					  "tsd-fault",
					  "irev-fault",
					  "vph-ov-hard",
					  "vph-ov-soft",
					  "ilim",
					  "temp-alarm";
			};
		};
	};

	smb1390_slave: qcom,smb1390_slave@18 {
		compatible = "qcom,i2c-pmic";
		reg = <0x18>;
		#address-cells = <1>;
		#size-cells = <0>;
		qcom,periph-map = <0x10>;
		status = "disabled";

		smb1390_slave_charger: qcom,charge_pump_slave {
			compatible = "qcom,smb1390-slave";
			status = "disabled";
		};
	};
};

&removed_region {
	reg = <0 0x86200000 0 0x4900000>;
};

/ {
	k61,dtbo-target = <&soc>;

	__symbols__ {
		soc = "/soc";
	};
};

